VERSION ""

NS_ :

BS_:

BU_:

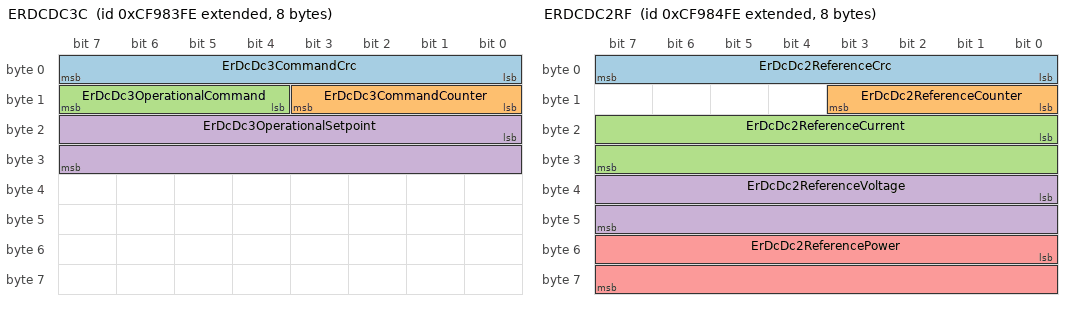
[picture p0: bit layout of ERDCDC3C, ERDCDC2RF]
BO_ 2365162494 ERDCDC3C: 8 Vector__XXX
 SG_ ErDcDc3CommandCrc : 0|8@1+ (1,0) [0|250] "count" Vector__XXX
 SG_ ErDcDc3CommandCounter : 8|4@1+ (1,0) [0|15] "" Vector__XXX
 SG_ ErDcDc3OperationalCommand : 12|4@1+ (1,0) [0|15] "" Vector__XXX
 SG_ ErDcDc3OperationalSetpoint : 16|16@1+ (0.00390625,-125) [-125|125.99609375] "%" Vector__XXX

BO_ 2365162750 ERDCDC2RF: 8 Vector__XXX
 SG_ ErDcDc2ReferenceCrc : 0|8@1+ (1,0) [0|250] "count" Vector__XXX
 SG_ ErDcDc2ReferenceCounter : 8|4@1+ (1,0) [0|15] "" Vector__XXX
 SG_ ErDcDc2ReferenceCurrent : 16|16@1+ (0.125,0) [0|8031.875] "A" Vector__XXX
 SG_ ErDcDc2ReferenceVoltage : 32|16@1+ (0.125,0) [0|8031.875] "V" Vector__XXX
 SG_ ErDcDc2ReferencePower : 48|16@1+ (0.0625,0) [0|4015.9375] "kW" Vector__XXX

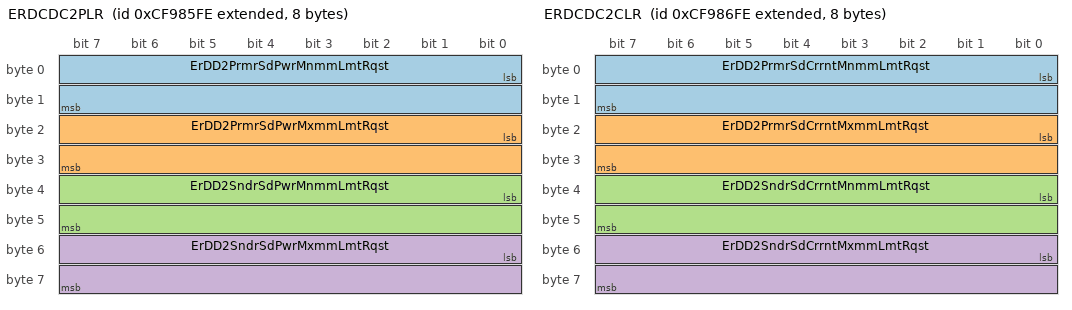
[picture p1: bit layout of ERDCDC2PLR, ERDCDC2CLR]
BO_ 2365163006 ERDCDC2PLR: 8 Vector__XXX
 SG_ ErDD2PrmrSdPwrMnmmLmtRqst : 0|16@1+ (0.00390625,-125) [-125|125.99609375] "%" Vector__XXX
 SG_ ErDD2PrmrSdPwrMxmmLmtRqst : 16|16@1+ (0.00390625,-125) [-125|125.99609375] "%" Vector__XXX
 SG_ ErDD2SndrSdPwrMnmmLmtRqst : 32|16@1+ (0.00390625,-125) [-125|125.99609375] "%" Vector__XXX
 SG_ ErDD2SndrSdPwrMxmmLmtRqst : 48|16@1+ (0.00390625,-125) [-125|125.99609375] "%" Vector__XXX

BO_ 2365163262 ERDCDC2CLR: 8 Vector__XXX
 SG_ ErDD2PrmrSdCrrntMnmmLmtRqst : 0|16@1+ (0.00390625,-125) [-125|125.99609375] "%" Vector__XXX
 SG_ ErDD2PrmrSdCrrntMxmmLmtRqst : 16|16@1+ (0.00390625,-125) [-125|125.99609375] "%" Vector__XXX
 SG_ ErDD2SndrSdCrrntMnmmLmtRqst : 32|16@1+ (0.00390625,-125) [-125|125.99609375] "%" Vector__XXX
 SG_ ErDD2SndrSdCrrntMxmmLmtRqst : 48|16@1+ (0.00390625,-125) [-125|125.99609375] "%" Vector__XXX

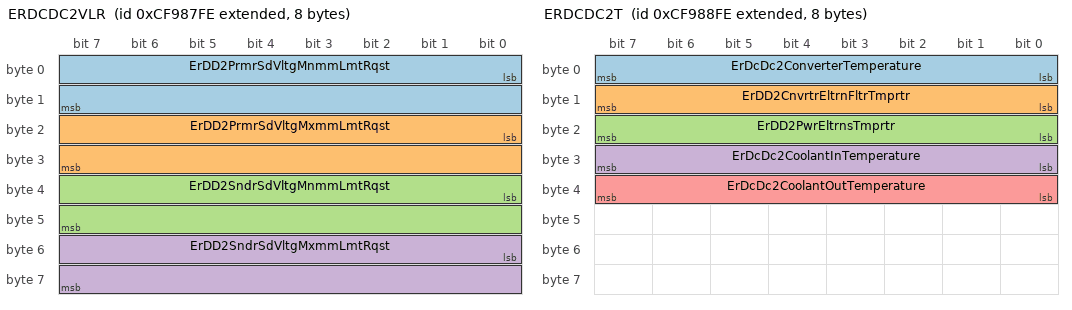
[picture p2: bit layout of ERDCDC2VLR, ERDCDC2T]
BO_ 2365163518 ERDCDC2VLR: 8 Vector__XXX
 SG_ ErDD2PrmrSdVltgMnmmLmtRqst : 0|16@1+ (0.00390625,-125) [0|125.99609375] "%" Vector__XXX
 SG_ ErDD2PrmrSdVltgMxmmLmtRqst : 16|16@1+ (0.00390625,-125) [0|125.99609375] "%" Vector__XXX
 SG_ ErDD2SndrSdVltgMnmmLmtRqst : 32|16@1+ (0.00390625,-125) [0|125.99609375] "%" Vector__XXX
 SG_ ErDD2SndrSdVltgMxmmLmtRqst : 48|16@1+ (0.00390625,-125) [0|125.99609375] "%" Vector__XXX

BO_ 2365163774 ERDCDC2T: 8 Vector__XXX
 SG_ ErDcDc2ConverterTemperature : 0|8@1+ (1,-40) [-40|210] "degC" Vector__XXX
 SG_ ErDD2CnvrtrEltrnFltrTmprtr : 8|8@1+ (1,-40) [-40|210] "degC" Vector__XXX
 SG_ ErDD2PwrEltrnsTmprtr : 16|8@1+ (1,-40) [-40|210] "degC" Vector__XXX
 SG_ ErDcDc2CoolantInTemperature : 24|8@1+ (1,-40) [-40|210] "degC" Vector__XXX
 SG_ ErDcDc2CoolantOutTemperature : 32|8@1+ (1,-40) [-40|210] "degC" Vector__XXX

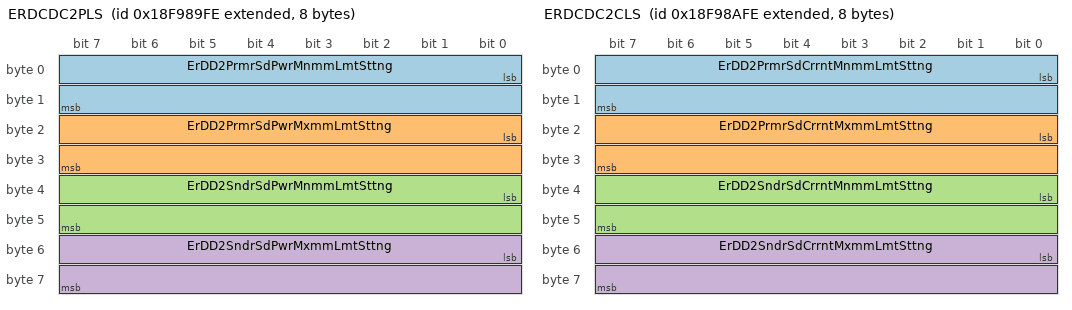
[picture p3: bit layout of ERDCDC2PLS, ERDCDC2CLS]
BO_ 2566490622 ERDCDC2PLS: 8 Vector__XXX
 SG_ ErDD2PrmrSdPwrMnmmLmtSttng : 0|16@1+ (0.00390625,-125) [-125|125.99609375] "%" Vector__XXX
 SG_ ErDD2PrmrSdPwrMxmmLmtSttng : 16|16@1+ (0.00390625,-125) [-125|125.99609375] "%" Vector__XXX
 SG_ ErDD2SndrSdPwrMnmmLmtSttng : 32|16@1+ (0.00390625,-125) [-125|125.99609375] "%" Vector__XXX
 SG_ ErDD2SndrSdPwrMxmmLmtSttng : 48|16@1+ (0.00390625,-125) [-125|125.99609375] "%" Vector__XXX

BO_ 2566490878 ERDCDC2CLS: 8 Vector__XXX
 SG_ ErDD2PrmrSdCrrntMnmmLmtSttng : 0|16@1+ (0.00390625,-125) [-125|125.99609375] "%" Vector__XXX
 SG_ ErDD2PrmrSdCrrntMxmmLmtSttng : 16|16@1+ (0.00390625,-125) [-125|125.99609375] "%" Vector__XXX
 SG_ ErDD2SndrSdCrrntMnmmLmtSttng : 32|16@1+ (0.00390625,-125) [-125|125.99609375] "%" Vector__XXX
 SG_ ErDD2SndrSdCrrntMxmmLmtSttng : 48|16@1+ (0.00390625,-125) [-125|125.99609375] "%" Vector__XXX

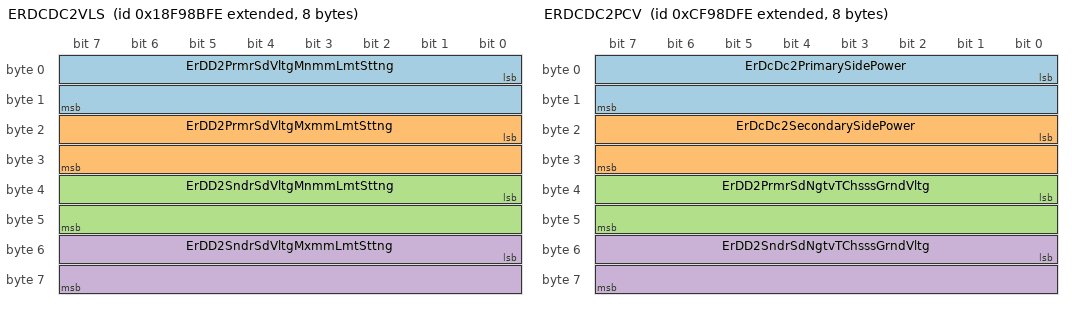
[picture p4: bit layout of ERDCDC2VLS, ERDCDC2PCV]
BO_ 2566491134 ERDCDC2VLS: 8 Vector__XXX
 SG_ ErDD2PrmrSdVltgMnmmLmtSttng : 0|16@1+ (0.00390625,-125) [0|125.99609375] "%" Vector__XXX
 SG_ ErDD2PrmrSdVltgMxmmLmtSttng : 16|16@1+ (0.00390625,-125) [0|125.99609375] "%" Vector__XXX
 SG_ ErDD2SndrSdVltgMnmmLmtSttng : 32|16@1+ (0.00390625,-125) [0|125.99609375] "%" Vector__XXX
 SG_ ErDD2SndrSdVltgMxmmLmtSttng : 48|16@1+ (0.00390625,-125) [0|125.99609375] "%" Vector__XXX

BO_ 2365164798 ERDCDC2LV: 8 Vector__XXX
 SG_ ErDD2CntrllrInptIgntnVltg : 0|16@1+ (0.05,0) [0|3212.75] "V" Vector__XXX
 SG_ ErDD2CntrllrInptUnswthdSlVltg : 16|16@1+ (0.05,0) [0|3212.75] "V" Vector__XXX

BO_ 2365165054 ERDCDC2PCV: 8 Vector__XXX
 SG_ ErDcDc2PrimarySidePower : 0|16@1+ (0.00390625,-125) [-125|125.99609375] "%" Vector__XXX
 SG_ ErDcDc2SecondarySidePower : 16|16@1+ (0.00390625,-125) [-125|125.99609375] "%" Vector__XXX
 SG_ ErDD2PrmrSdNgtvTChsssGrndVltg : 32|16@1+ (0.00390625,-125) [0|125.99609375] "%" Vector__XXX
 SG_ ErDD2SndrSdNgtvTChsssGrndVltg : 48|16@1+ (0.00390625,-125) [0|125.99609375] "%" Vector__XXX

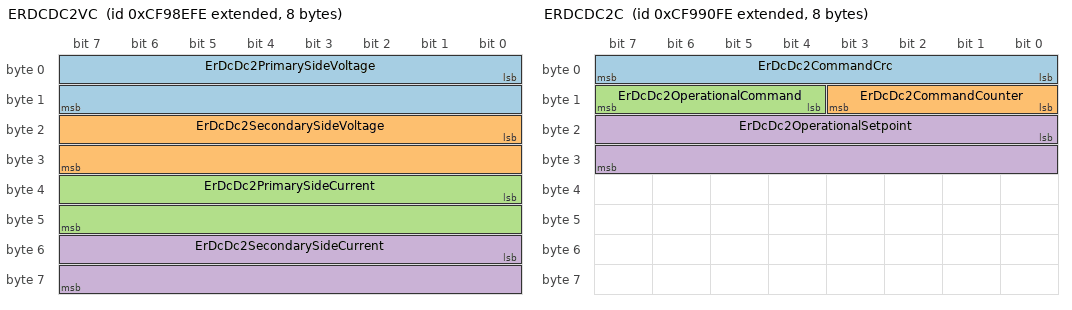
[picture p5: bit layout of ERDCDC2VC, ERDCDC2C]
BO_ 2365165310 ERDCDC2VC: 8 Vector__XXX
 SG_ ErDcDc2PrimarySideVoltage : 0|16@1+ (0.00390625,-125) [0|125.99609375] "%" Vector__XXX
 SG_ ErDcDc2SecondarySideVoltage : 16|16@1+ (0.00390625,-125) [0|125.99609375] "%" Vector__XXX
 SG_ ErDcDc2PrimarySideCurrent : 32|16@1+ (0.00390625,-125) [-125|125.99609375] "%" Vector__XXX
 SG_ ErDcDc2SecondarySideCurrent : 48|16@1+ (0.00390625,-125) [-125|125.99609375] "%" Vector__XXX

BO_ 2365165566 ERDCDC2OS: 8 Vector__XXX
 SG_ ErDcDc2StatusCrc : 0|8@1+ (1,0) [0|250] "count" Vector__XXX
 SG_ ErDcDc2StatusCounter : 8|4@1+ (1,0) [0|15] "" Vector__XXX
 SG_ ErDcDc2OperationalStatus : 12|4@1+ (1,0) [0|15] "" Vector__XXX
 SG_ ErDcDc2HvilStatus : 16|2@1+ (1,0) [0|3] "" Vector__XXX
 SG_ ErDcDc2LoadshedRequest : 18|2@1+ (1,0) [0|3] "" Vector__XXX
 SG_ ErDD2PwrLmtDTPrmrSdCrrntMnmm : 20|2@1+ (1,0) [0|3] "" Vector__XXX
 SG_ ErDD2PwrLmtDTPrmrSdCrrntMxmm : 22|2@1+ (1,0) [0|3] "" Vector__XXX
 SG_ ErDD2PwrLmtDTSndrSdCrrntMnmm : 24|2@1+ (1,0) [0|3] "" Vector__XXX
 SG_ ErDD2PwrLmtDTSndrSdCrrntMxmm : 26|2@1+ (1,0) [0|3] "" Vector__XXX
 SG_ ErDD2PwrLmtDTPrmrSdVltgMnmm : 28|2@1+ (1,0) [0|3] "" Vector__XXX
 SG_ ErDD2PwrLmtDTPrmrSdVltgMxmm : 30|2@1+ (1,0) [0|3] "" Vector__XXX
 SG_ ErDD2PwrLmtDTSndrSdVltgMnmm : 32|2@1+ (1,0) [0|3] "" Vector__XXX
 SG_ ErDD2PwrLmtDTSndrSdVltgMxmm : 34|2@1+ (1,0) [0|3] "" Vector__XXX
 SG_ ErDD2PwrLmtDTCnvrtrTmprtr : 36|2@1+ (1,0) [0|3] "" Vector__XXX
 SG_ ErDD2PwrLmtDTEltrnFltrTmprtr : 38|2@1+ (1,0) [0|3] "" Vector__XXX
 SG_ ErDD2PwrLmtDTPwrEltrnsTmprtr : 40|2@1+ (1,0) [0|3] "" Vector__XXX
 SG_ ErDD2PwrLmtDTUndfndRsn : 42|2@1+ (1,0) [0|3] "" Vector__XXX

BO_ 2365165822 ERDCDC2C: 8 Vector__XXX
 SG_ ErDcDc2CommandCrc : 0|8@1+ (1,0) [0|250] "count" Vector__XXX
 SG_ ErDcDc2CommandCounter : 8|4@1+ (1,0) [0|15] "" Vector__XXX
 SG_ ErDcDc2OperationalCommand : 12|4@1+ (1,0) [0|15] "" Vector__XXX
 SG_ ErDcDc2OperationalSetpoint : 16|16@1+ (0.00390625,-125) [-125|125.99609375] "%" Vector__XXX

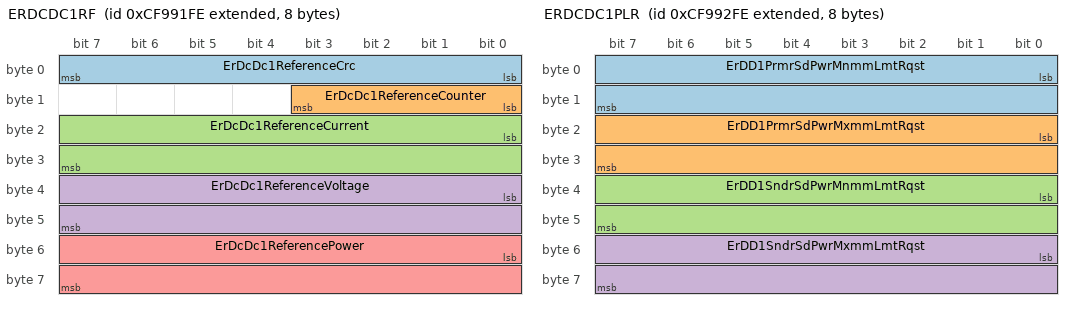
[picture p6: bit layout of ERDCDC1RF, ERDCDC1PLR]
BO_ 2365166078 ERDCDC1RF: 8 Vector__XXX
 SG_ ErDcDc1ReferenceCrc : 0|8@1+ (1,0) [0|250] "count" Vector__XXX
 SG_ ErDcDc1ReferenceCounter : 8|4@1+ (1,0) [0|15] "" Vector__XXX
 SG_ ErDcDc1ReferenceCurrent : 16|16@1+ (0.125,0) [0|8031.875] "A" Vector__XXX
 SG_ ErDcDc1ReferenceVoltage : 32|16@1+ (0.125,0) [0|8031.875] "V" Vector__XXX
 SG_ ErDcDc1ReferencePower : 48|16@1+ (0.0625,0) [0|4015.9375] "kW" Vector__XXX

BO_ 2365166334 ERDCDC1PLR: 8 Vector__XXX
 SG_ ErDD1PrmrSdPwrMnmmLmtRqst : 0|16@1+ (0.00390625,-125) [-125|125.99609375] "%" Vector__XXX
 SG_ ErDD1PrmrSdPwrMxmmLmtRqst : 16|16@1+ (0.00390625,-125) [-125|125.99609375] "%" Vector__XXX
 SG_ ErDD1SndrSdPwrMnmmLmtRqst : 32|16@1+ (0.00390625,-125) [-125|125.99609375] "%" Vector__XXX
 SG_ ErDD1SndrSdPwrMxmmLmtRqst : 48|16@1+ (0.00390625,-125) [-125|125.99609375] "%" Vector__XXX

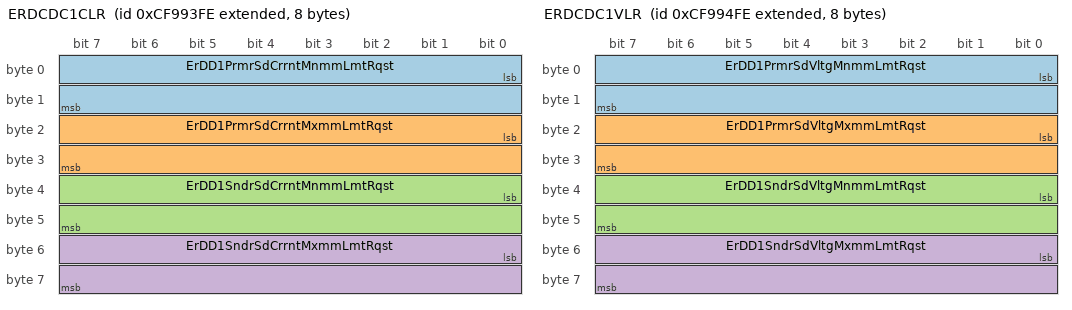
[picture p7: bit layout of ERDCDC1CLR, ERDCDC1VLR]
BO_ 2365166590 ERDCDC1CLR: 8 Vector__XXX
 SG_ ErDD1PrmrSdCrrntMnmmLmtRqst : 0|16@1+ (0.00390625,-125) [-125|125.99609375] "%" Vector__XXX
 SG_ ErDD1PrmrSdCrrntMxmmLmtRqst : 16|16@1+ (0.00390625,-125) [-125|125.99609375] "%" Vector__XXX
 SG_ ErDD1SndrSdCrrntMnmmLmtRqst : 32|16@1+ (0.00390625,-125) [-125|125.99609375] "%" Vector__XXX
 SG_ ErDD1SndrSdCrrntMxmmLmtRqst : 48|16@1+ (0.00390625,-125) [-125|125.99609375] "%" Vector__XXX

BO_ 2365166846 ERDCDC1VLR: 8 Vector__XXX
 SG_ ErDD1PrmrSdVltgMnmmLmtRqst : 0|16@1+ (0.00390625,-125) [0|125.99609375] "%" Vector__XXX
 SG_ ErDD1PrmrSdVltgMxmmLmtRqst : 16|16@1+ (0.00390625,-125) [0|125.99609375] "%" Vector__XXX
 SG_ ErDD1SndrSdVltgMnmmLmtRqst : 32|16@1+ (0.00390625,-125) [0|125.99609375] "%" Vector__XXX
 SG_ ErDD1SndrSdVltgMxmmLmtRqst : 48|16@1+ (0.00390625,-125) [0|125.99609375] "%" Vector__XXX

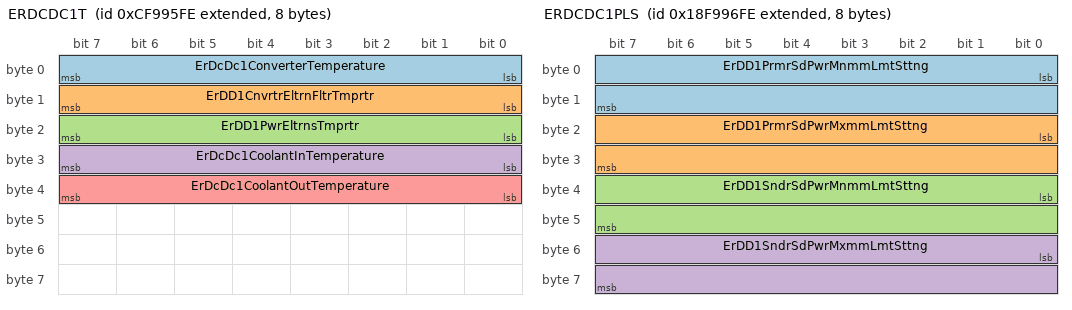
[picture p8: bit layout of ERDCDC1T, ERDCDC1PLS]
BO_ 2365167102 ERDCDC1T: 8 Vector__XXX
 SG_ ErDcDc1ConverterTemperature : 0|8@1+ (1,-40) [-40|210] "degC" Vector__XXX
 SG_ ErDD1CnvrtrEltrnFltrTmprtr : 8|8@1+ (1,-40) [-40|210] "degC" Vector__XXX
 SG_ ErDD1PwrEltrnsTmprtr : 16|8@1+ (1,-40) [-40|210] "degC" Vector__XXX
 SG_ ErDcDc1CoolantInTemperature : 24|8@1+ (1,-40) [-40|210] "degC" Vector__XXX
 SG_ ErDcDc1CoolantOutTemperature : 32|8@1+ (1,-40) [-40|210] "degC" Vector__XXX

BO_ 2566493950 ERDCDC1PLS: 8 Vector__XXX
 SG_ ErDD1PrmrSdPwrMnmmLmtSttng : 0|16@1+ (0.00390625,-125) [-125|125.99609375] "%" Vector__XXX
 SG_ ErDD1PrmrSdPwrMxmmLmtSttng : 16|16@1+ (0.00390625,-125) [-125|125.99609375] "%" Vector__XXX
 SG_ ErDD1SndrSdPwrMnmmLmtSttng : 32|16@1+ (0.00390625,-125) [-125|125.99609375] "%" Vector__XXX
 SG_ ErDD1SndrSdPwrMxmmLmtSttng : 48|16@1+ (0.00390625,-125) [-125|125.99609375] "%" Vector__XXX

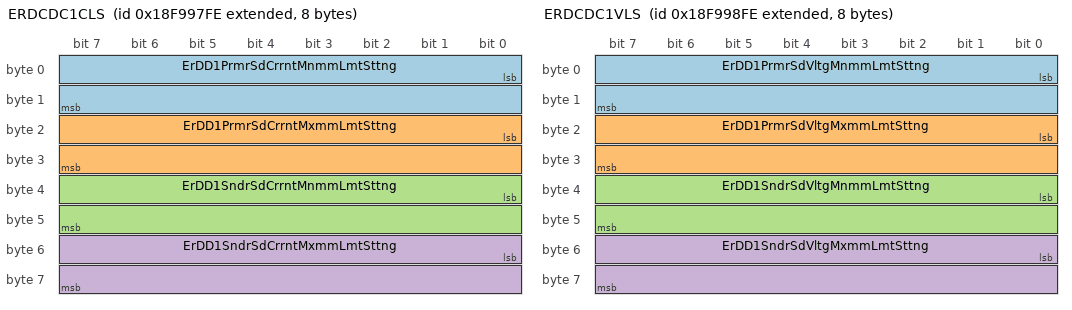
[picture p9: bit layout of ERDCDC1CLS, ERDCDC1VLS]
BO_ 2566494206 ERDCDC1CLS: 8 Vector__XXX
 SG_ ErDD1PrmrSdCrrntMnmmLmtSttng : 0|16@1+ (0.00390625,-125) [-125|125.99609375] "%" Vector__XXX
 SG_ ErDD1PrmrSdCrrntMxmmLmtSttng : 16|16@1+ (0.00390625,-125) [-125|125.99609375] "%" Vector__XXX
 SG_ ErDD1SndrSdCrrntMnmmLmtSttng : 32|16@1+ (0.00390625,-125) [-125|125.99609375] "%" Vector__XXX
 SG_ ErDD1SndrSdCrrntMxmmLmtSttng : 48|16@1+ (0.00390625,-125) [-125|125.99609375] "%" Vector__XXX

BO_ 2566494462 ERDCDC1VLS: 8 Vector__XXX
 SG_ ErDD1PrmrSdVltgMnmmLmtSttng : 0|16@1+ (0.00390625,-125) [0|125.99609375] "%" Vector__XXX
 SG_ ErDD1PrmrSdVltgMxmmLmtSttng : 16|16@1+ (0.00390625,-125) [0|125.99609375] "%" Vector__XXX
 SG_ ErDD1SndrSdVltgMnmmLmtSttng : 32|16@1+ (0.00390625,-125) [0|125.99609375] "%" Vector__XXX
 SG_ ErDD1SndrSdVltgMxmmLmtSttng : 48|16@1+ (0.00390625,-125) [0|125.99609375] "%" Vector__XXX

BO_ 2365168126 ERDCDC1LV: 8 Vector__XXX
 SG_ ErDD1CntrllrInptIgntnVltg : 0|16@1+ (0.05,0) [0|3212.75] "V" Vector__XXX
 SG_ ErDD1CntrllrInptUnswthdSlVltg : 16|16@1+ (0.05,0) [0|3212.75] "V" Vector__XXX

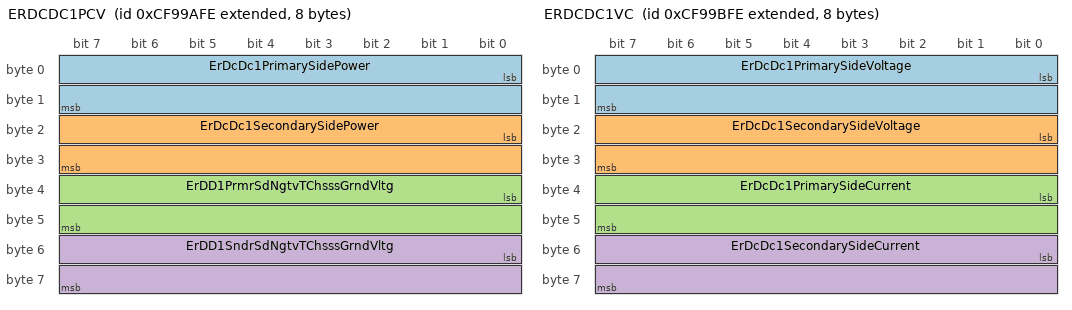
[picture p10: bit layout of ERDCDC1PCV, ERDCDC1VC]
BO_ 2365168382 ERDCDC1PCV: 8 Vector__XXX
 SG_ ErDcDc1PrimarySidePower : 0|16@1+ (0.00390625,-125) [-125|125.99609375] "%" Vector__XXX
 SG_ ErDcDc1SecondarySidePower : 16|16@1+ (0.00390625,-125) [-125|125.99609375] "%" Vector__XXX
 SG_ ErDD1PrmrSdNgtvTChsssGrndVltg : 32|16@1+ (0.00390625,-125) [0|125.99609375] "%" Vector__XXX
 SG_ ErDD1SndrSdNgtvTChsssGrndVltg : 48|16@1+ (0.00390625,-125) [0|125.99609375] "%" Vector__XXX

BO_ 2365168638 ERDCDC1VC: 8 Vector__XXX
 SG_ ErDcDc1PrimarySideVoltage : 0|16@1+ (0.00390625,-125) [0|125.99609375] "%" Vector__XXX
 SG_ ErDcDc1SecondarySideVoltage : 16|16@1+ (0.00390625,-125) [0|125.99609375] "%" Vector__XXX
 SG_ ErDcDc1PrimarySideCurrent : 32|16@1+ (0.00390625,-125) [-125|125.99609375] "%" Vector__XXX
 SG_ ErDcDc1SecondarySideCurrent : 48|16@1+ (0.00390625,-125) [-125|125.99609375] "%" Vector__XXX

BO_ 2365168894 ERDCDC1OS: 8 Vector__XXX
 SG_ ErDcDc1StatusCrc : 0|8@1+ (1,0) [0|250] "count" Vector__XXX
 SG_ ErDcDc1StatusCounter : 8|4@1+ (1,0) [0|15] "" Vector__XXX
 SG_ ErDcDc1OperationalStatus : 12|4@1+ (1,0) [0|15] "" Vector__XXX
 SG_ ErDcDc1HvilStatus : 16|2@1+ (1,0) [0|3] "" Vector__XXX
 SG_ ErDcDc1LoadshedRequest : 18|2@1+ (1,0) [0|3] "" Vector__XXX
 SG_ ErDD1PwrLmtDTPrmrSdCrrntMnmm : 20|2@1+ (1,0) [0|3] "" Vector__XXX
 SG_ ErDD1PwrLmtDTPrmrSdCrrntMxmm : 22|2@1+ (1,0) [0|3] "" Vector__XXX
 SG_ ErDD1PwrLmtDTSndrSdCrrntMnmm : 24|2@1+ (1,0) [0|3] "" Vector__XXX
 SG_ ErDD1PwrLmtDTSndrSdCrrntMxmm : 26|2@1+ (1,0) [0|3] "" Vector__XXX
 SG_ ErDD1PwrLmtDTPrmrSdVltgMnmm : 28|2@1+ (1,0) [0|3] "" Vector__XXX
 SG_ ErDD1PwrLmtDTPrmrSdVltgMxmm : 30|2@1+ (1,0) [0|3] "" Vector__XXX
 SG_ ErDD1PwrLmtDTSndrSdVltgMnmm : 32|2@1+ (1,0) [0|3] "" Vector__XXX
 SG_ ErDD1PwrLmtDTSndrSdVltgMxmm : 34|2@1+ (1,0) [0|3] "" Vector__XXX
 SG_ ErDD1PwrLmtDTCnvrtrTmprtr : 36|2@1+ (1,0) [0|3] "" Vector__XXX
 SG_ ErDD1PwrLmtDTEltrnFltrTmprtr : 38|2@1+ (1,0) [0|3] "" Vector__XXX
 SG_ ErDD1PwrLmtDTPwrEltrnsTmprtr : 40|2@1+ (1,0) [0|3] "" Vector__XXX
 SG_ ErDD1PwrLmtDTUndfndRsn : 42|2@1+ (1,0) [0|3] "" Vector__XXX

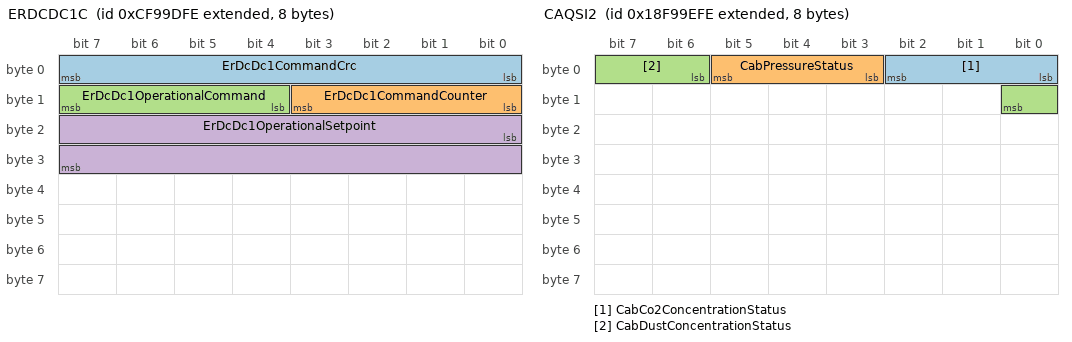
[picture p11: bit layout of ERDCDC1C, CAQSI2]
BO_ 2365169150 ERDCDC1C: 8 Vector__XXX
 SG_ ErDcDc1CommandCrc : 0|8@1+ (1,0) [0|250] "count" Vector__XXX
 SG_ ErDcDc1CommandCounter : 8|4@1+ (1,0) [0|15] "" Vector__XXX
 SG_ ErDcDc1OperationalCommand : 12|4@1+ (1,0) [0|15] "" Vector__XXX
 SG_ ErDcDc1OperationalSetpoint : 16|16@1+ (0.00390625,-125) [-125|125.99609375] "%" Vector__XXX

BO_ 2566495998 CAQSI2: 8 Vector__XXX
 SG_ CabCo2ConcentrationStatus : 0|3@1+ (1,0) [0|7] "" Vector__XXX
 SG_ CabPressureStatus : 3|3@1+ (1,0) [0|7] "" Vector__XXX
 SG_ CabDustConcentrationStatus : 6|3@1+ (1,0) [0|7] "" Vector__XXX

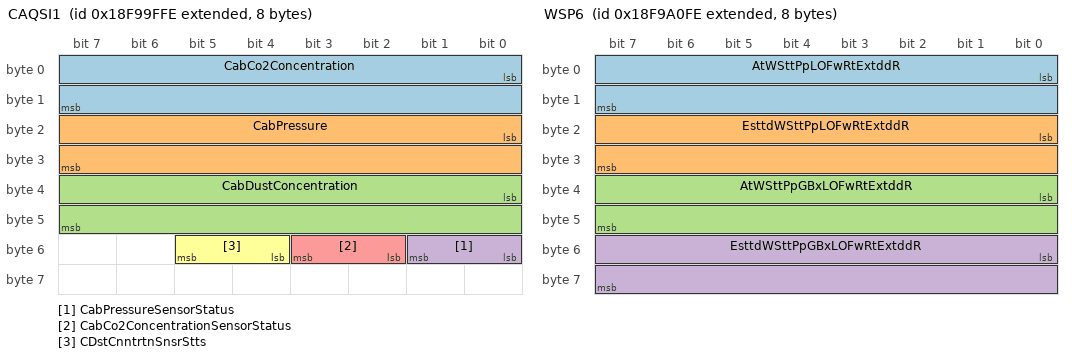
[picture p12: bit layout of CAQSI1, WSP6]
BO_ 2566496254 CAQSI1: 8 Vector__XXX
 SG_ CabCo2Concentration : 0|16@1+ (1,0) [0|64255] "ppm" Vector__XXX
 SG_ CabPressure : 16|16@1+ (0.0078125,-250) [-100|251.9921875] "kPa" Vector__XXX
 SG_ CabDustConcentration : 32|16@1+ (1,-25) [-25|64230] "microg/m3" Vector__XXX
 SG_ CabPressureSensorStatus : 48|2@1+ (1,0) [0|3] "" Vector__XXX
 SG_ CabCo2ConcentrationSensorStatus : 50|2@1+ (1,0) [0|3] "" Vector__XXX
 SG_ CDstCnntrtnSnsrStts : 52|2@1+ (1,0) [0|3] "" Vector__XXX

BO_ 2566496510 WSP6: 8 Vector__XXX
 SG_ AtWSttPpLOFwRtExtddR : 0|16@1+ (0.5,0) [0|32127.5] "l/min" Vector__XXX
 SG_ EsttdWSttPpLOFwRtExtddR : 16|16@1+ (0.5,0) [0|32127.5] "l/min" Vector__XXX
 SG_ AtWSttPpGBxLOFwRtExtddR : 32|16@1+ (0.5,0) [0|32127.5] "l/min" Vector__XXX
 SG_ EsttdWSttPpGBxLOFwRtExtddR : 48|16@1+ (0.5,0) [0|32127.5] "l/min" Vector__XXX

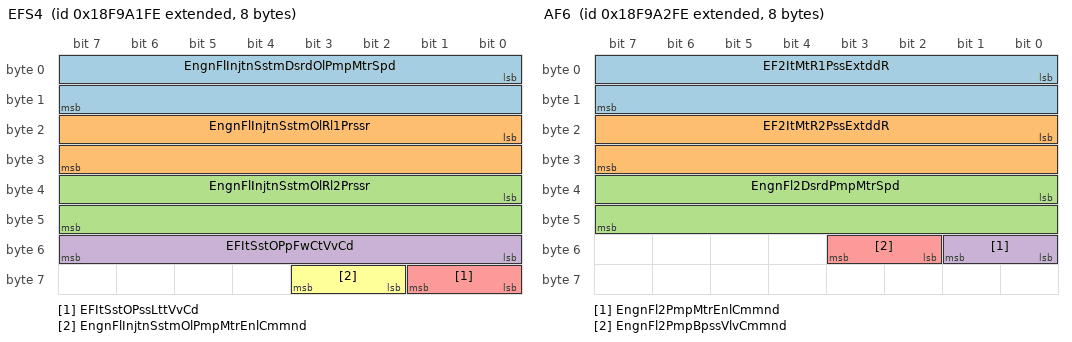
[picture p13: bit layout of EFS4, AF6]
BO_ 2566496766 EFS4: 8 Vector__XXX
 SG_ EngnFlInjtnSstmDsrdOlPmpMtrSpd : 0|16@1+ (0.5,0) [0|32127.5] "rpm" Vector__XXX
 SG_ EngnFlInjtnSstmOlRl1Prssr : 16|16@1+ (0.00390625,0) [0|250.99609375] "MPa" Vector__XXX
 SG_ EngnFlInjtnSstmOlRl2Prssr : 32|16@1+ (0.00390625,0) [0|250.99609375] "MPa" Vector__XXX
 SG_ EFItSstOPpFwCtVvCd : 48|8@1+ (0.4,0) [0|100] "%" Vector__XXX
 SG_ EFItSstOPssLttVvCd : 56|2@1+ (1,0) [0|3] "" Vector__XXX
 SG_ EngnFlInjtnSstmOlPmpMtrEnlCmmnd : 58|2@1+ (1,0) [0|3] "" Vector__XXX

BO_ 2566497022 AF6: 8 Vector__XXX
 SG_ EF2ItMtR1PssExtddR : 0|16@1+ (0.00390625,0) [0|250.99609375] "MPa" Vector__XXX
 SG_ EF2ItMtR2PssExtddR : 16|16@1+ (0.00390625,0) [0|250.99609375] "MPa" Vector__XXX
 SG_ EngnFl2DsrdPmpMtrSpd : 32|16@1+ (0.5,0) [0|32127.5] "rpm" Vector__XXX
 SG_ EngnFl2PmpMtrEnlCmmnd : 48|2@1+ (1,0) [0|3] "" Vector__XXX
 SG_ EngnFl2PmpBpssVlvCmmnd : 50|2@1+ (1,0) [0|3] "" Vector__XXX

BO_ 2566497278 ECDAC: 8 Vector__XXX
 SG_ EngnCtlstDvrtrAttr1Cmmnd : 0|8@1+ (0.4,0) [0|100] "%" Vector__XXX
 SG_ EngnCtlstDvrtrAttr2Cmmnd : 8|8@1+ (0.4,0) [0|100] "%" Vector__XXX

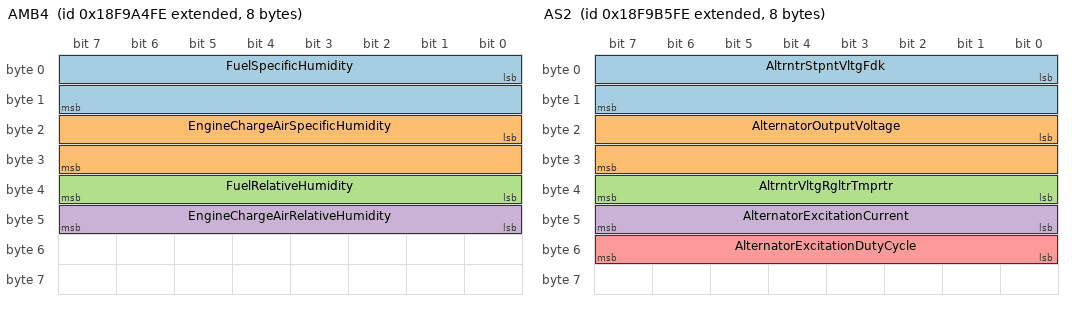
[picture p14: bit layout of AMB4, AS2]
BO_ 2566497534 AMB4: 8 Vector__XXX
 SG_ FuelSpecificHumidity : 0|16@1+ (0.01,0) [0|642.55] "g/kg" Vector__XXX
 SG_ EngineChargeAirSpecificHumidity : 16|16@1+ (0.01,0) [0|642.55] "g/kg" Vector__XXX
 SG_ FuelRelativeHumidity : 32|8@1+ (0.4,0) [0|100] "%" Vector__XXX
 SG_ EngineChargeAirRelativeHumidity : 40|8@1+ (0.4,0) [0|100] "%" Vector__XXX

BO_ 2566497790 EEPCSI2: 8 Vector__XXX
 SG_ Atttt2ExstPttCtSstDstT : 0|32@1+ (1,0) [0|4211081215] "s" Vector__XXX
 SG_ Atttt2ExstPttCtSstDstCt : 32|32@1+ (1,0) [0|4211081215] "count" Vector__XXX

BO_ 2566498046 EEPCSI1: 8 Vector__XXX
 SG_ Atttt1ExstPttCtSstDstT : 0|32@1+ (1,0) [0|4211081215] "s" Vector__XXX
 SG_ Atttt1ExstPttCtSstDstCt : 32|32@1+ (1,0) [0|4211081215] "count" Vector__XXX

BO_ 2566498302 ASI20: 8 Vector__XXX
 SG_ Atttt2TtERtWtNDsExstFdDv : 0|32@1+ (1,0) [0|4211081215] "s" Vector__XXX
 SG_ Atttt2TtEvtCtWtNDsExstFdDv : 32|32@1+ (1,0) [0|4211081215] "count" Vector__XXX

BO_ 2566498558 ASI19: 8 Vector__XXX
 SG_ Aftrtrtmnt2SrIntkHghTmprtrTm : 0|32@1+ (1,0) [0|4211081215] "s" Vector__XXX
 SG_ Aftrtrtmnt2SrIntkHghTmprtrCnt : 32|32@1+ (1,0) [0|4211081215] "count" Vector__XXX

BO_ 2566498814 ASI18: 8 Vector__XXX
 SG_ Aftrtrtmnt2DslExhstFldFrznTm : 0|32@1+ (1,0) [0|4211081215] "s" Vector__XXX
 SG_ Aftrtrtmnt2DslExhstFldFrznCnt : 32|32@1+ (1,0) [0|4211081215] "count" Vector__XXX

BO_ 2566499070 ASI17: 8 Vector__XXX
 SG_ Aftrtrtmnt2SrMlfntnTm : 0|32@1+ (1,0) [0|4211081215] "s" Vector__XXX
 SG_ Aftrtrtmnt2SrMlfntnCnt : 32|32@1+ (1,0) [0|4211081215] "count" Vector__XXX

BO_ 2566499326 ASI16: 8 Vector__XXX
 SG_ Atttt2DsExstFdQtMtT : 0|32@1+ (1,0) [0|4211081215] "s" Vector__XXX
 SG_ Atttt2DsExstFdQtMtCt : 32|32@1+ (1,0) [0|4211081215] "count" Vector__XXX

BO_ 2566499582 ASI15: 8 Vector__XXX
 SG_ Atttt2DsExstFdT1EptT : 0|32@1+ (1,0) [0|4211081215] "s" Vector__XXX
 SG_ Atttt2DsExstFdT1EptCt : 32|32@1+ (1,0) [0|4211081215] "count" Vector__XXX

BO_ 2566499838 ASI14: 8 Vector__XXX
 SG_ AttttTtERtWtNDsExstFdDv : 0|32@1+ (1,0) [0|4211081215] "s" Vector__XXX
 SG_ AttttTtEvtCtWtNDsExstFdDv : 32|32@1+ (1,0) [0|4211081215] "count" Vector__XXX

BO_ 2566500094 ASI13: 8 Vector__XXX
 SG_ AftrtrtmntSrIntkHghTmprtrTm : 0|32@1+ (1,0) [0|4211081215] "s" Vector__XXX
 SG_ AftrtrtmntSrIntkHghTmprtrCnt : 32|32@1+ (1,0) [0|4211081215] "count" Vector__XXX

BO_ 2566500350 ASI12: 8 Vector__XXX
 SG_ Aftrtrtmnt1DslExhstFldFrznTm : 0|32@1+ (1,0) [0|4211081215] "s" Vector__XXX
 SG_ Aftrtrtmnt1DslExhstFldFrznCnt : 32|32@1+ (1,0) [0|4211081215] "count" Vector__XXX

BO_ 2566500606 ASI11: 8 Vector__XXX
 SG_ Aftrtrtmnt1SrMlfntnTm : 0|32@1+ (1,0) [0|4211081215] "s" Vector__XXX
 SG_ Aftrtrtmnt1SrMlfntnCnt : 32|32@1+ (1,0) [0|4211081215] "count" Vector__XXX

BO_ 2566500862 ASI10: 8 Vector__XXX
 SG_ Atttt1DsExstFdQtMtT : 0|32@1+ (1,0) [0|4211081215] "s" Vector__XXX
 SG_ Atttt1DsExstFdQtMtCt : 32|32@1+ (1,0) [0|4211081215] "count" Vector__XXX

BO_ 2566501118 ASI9: 8 Vector__XXX
 SG_ Atttt1DsExstFdT1EptT : 0|32@1+ (1,0) [0|4211081215] "s" Vector__XXX
 SG_ Atttt1DsExstFdT1EptCt : 32|32@1+ (1,0) [0|4211081215] "count" Vector__XXX

BO_ 2499392766 GSF2: 8 Vector__XXX
 SG_ SmltdMnsFrqnOffstExtnddRng : 0|16@1+ (0.01,-321.28) [-321.28|321.27] "Hz" Vector__XXX

BO_ 2566501886 AS2: 8 Vector__XXX
 SG_ AltrntrStpntVltgFdk : 0|16@1+ (0.001,0) [0|64.255] "V" Vector__XXX
 SG_ AlternatorOutputVoltage : 16|16@1+ (0.001,0) [0|64.255] "V" Vector__XXX
 SG_ AltrntrVltgRgltrTmprtr : 32|8@1+ (1,-40) [-40|210] "degC" Vector__XXX
 SG_ AlternatorExcitationCurrent : 40|8@1+ (0.25,0) [0|62.5] "A" Vector__XXX
 SG_ AlternatorExcitationDutyCycle : 48|8@1+ (0.4,0) [0|100] "%" Vector__XXX

BO_ 2499417598 GSF: 8 Vector__XXX
 SG_ RtvPwrRmtInptCmpnstnFtr : 32|16@1+ (0.01,-321.27) [-321.27|321.28] "%" Vector__XXX
 SG_ RlPwrRmtInptCmpnstnFtr : 48|16@1+ (0.01,-321.27) [-321.27|321.28] "%" Vector__XXX

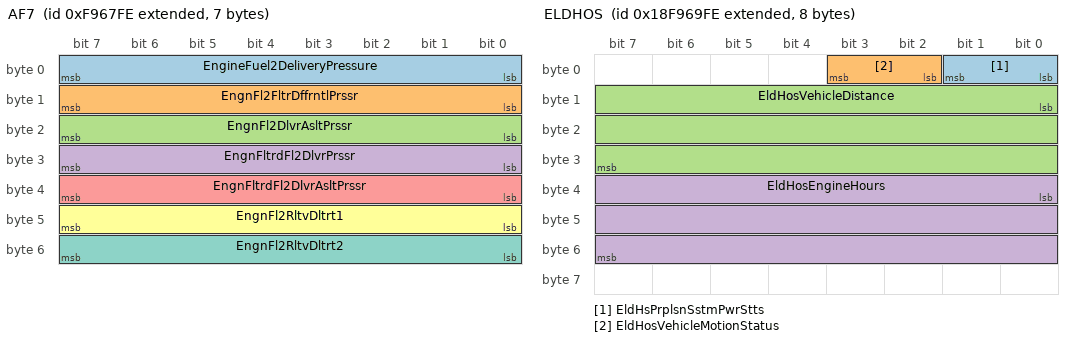
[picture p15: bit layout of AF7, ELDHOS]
BO_ 2163828734 AF7: 7 Vector__XXX
 SG_ EngineFuel2DeliveryPressure : 0|8@1+ (4,0) [0|1000] "kPa" Vector__XXX
 SG_ EngnFl2FltrDffrntlPrssr : 8|8@1+ (2,0) [0|500] "kPa" Vector__XXX
 SG_ EngnFl2DlvrAsltPrssr : 16|8@1+ (4,0) [0|1000] "kPa" Vector__XXX
 SG_ EngnFltrdFl2DlvrPrssr : 24|8@1+ (4,0) [0|1000] "kPa" Vector__XXX
 SG_ EngnFltrdFl2DlvrAsltPrssr : 32|8@1+ (4,0) [0|1000] "kPa" Vector__XXX
 SG_ EngnFl2RltvDltrt1 : 40|8@1+ (0.25,0) [0|62.5] "" Vector__XXX
 SG_ EngnFl2RltvDltrt2 : 48|8@1+ (0.25,0) [0|62.5] "" Vector__XXX

BO_ 2566482174 ECDAI: 8 Vector__XXX
 SG_ EngnCtlstDvrtrAttr1Pstn : 0|8@1+ (0.4,0) [0|100] "%" Vector__XXX
 SG_ EngnCtlstDvrtrAttr2Pstn : 8|8@1+ (0.4,0) [0|100] "%" Vector__XXX

BO_ 2566482430 ELDHOS: 8 Vector__XXX
 SG_ EldHsPrplsnSstmPwrStts : 0|2@1+ (1,0) [0|3] "" Vector__XXX
 SG_ EldHosVehicleMotionStatus : 2|2@1+ (1,0) [0|3] "" Vector__XXX
 SG_ EldHosVehicleDistance : 8|24@1+ (1.6,0) [0|26319256] "km" Vector__XXX
 SG_ EldHosEngineHours : 32|24@1+ (0.1,0) [0|1644953.5] "h" Vector__XXX

CM_ BO_ 2365162494 "ER DC/DC Converter 3 Control";
CM_ SG_ 2365162494 ErDcDc3CommandCrc "ER DC/DC 3 Command CRC: The CRC is defined as follows: - Length: 8 bits- Polynomial: x^8+x^5+x^3+x^2+x+1- Initial Value: FFh- Input Data Reflection: Not reflected- Result Data Reflection: Not reflected- XOR value: FFh SAE makes no claim of the functi...";
CM_ SG_ 2365162494 ErDcDc3CommandCounter "ER DC/DC 3 Command  Counter: The message counter is used to detect situations where the transmitting ECU malfunction repeats the same frame all the time. The receiver of the information may use the counter parameter to detect this situation. The tran...";
CM_ SG_ 2365162494 ErDcDc3OperationalCommand "ER DC/DC 3 Operational Command: Command to enable or disable operation.0000b = Disable - in this mode all high voltage switching is disabled0001b = Standby - system is ready and waiting for command to enter control modes0010b = Power Down - stop all ...";
CM_ SG_ 2365162494 ErDcDc3OperationalSetpoint "ER DC/DC 3 Operational Setpoint: The set point for regulating the DC/DC Converter per SPN 24151 (ER DC/DC 3 Operational Command).  When in Voltage control modes (states 0100b and 0101b of SPN 24151 (ER DC/DC 3 Operational Command)), the operational r...";
CM_ BO_ 2365162750 "ER DC/DC Converter 2 References";
CM_ SG_ 2365162750 ErDcDc2ReferenceCrc "ER DC/DC 2 Reference CRC: The CRC is defined as follows: - Length: 8 bits- Polynomial: x^8+x^5+x^3+x^2+x+1- Initial Value: FFh- Input Data Reflection: Not reflected- Result Data Reflection: Not reflected- XOR value: FFh SAE makes no claim of the func...";
CM_ SG_ 2365162750 ErDcDc2ReferenceCounter "ER DC/DC 2 Reference Counter: The message counter is used to detect situations where the transmitting ECU malfunction repeats the same frame all the time. The receiver of the information may use the counter parameter to detect this situation. The tra...";
CM_ SG_ 2365162750 ErDcDc2ReferenceCurrent "ER DC/DC 2 Reference Current: This value is used for converting inverter current in percent to units of Amps (RMS or DC).(Value in Amps) = (Percent Value)/(100%) * (Reference Current)For example, if this parameter has a value of 200 A and the percent...";
CM_ SG_ 2365162750 ErDcDc2ReferenceVoltage "ER DC/DC 2 Reference Voltage: This value is used for converting inverter voltage in percent to units of Volts (RMS or DC).(Value in Volts) = (Percent Value)/(100%) * (Reference Voltage)For example, if this parameter has a value of 400 V and the perce...";
CM_ SG_ 2365162750 ErDcDc2ReferencePower "ER DC/DC 2 Reference Power: This value is used for converting power in percent to units of kW.  (Value in kW) = (Percent Value)/(100%) * (Reference Power)For example, if this parameter has a value of 400 kW and the percent value is equal to 75%, then...";
CM_ BO_ 2365163006 "ER DC/DC Converter 2 Power Limits Request";
CM_ SG_ 2365163006 ErDD2PrmrSdPwrMnmmLmtRqst "ER DC/DC 2 Primary Side Power Minimum Limit Request: The minimum allowed primary side power requested by a separate device.   Under normal conditions this requested limit would be reflected in SPN 24123 (ER DC/DC 2 Primary Side Power Minimum Limit Se...";
CM_ SG_ 2365163006 ErDD2PrmrSdPwrMxmmLmtRqst "ER DC/DC 2 Primary Side Power Maximum Limit Request: The maximum allowed primary side power requested by a separate device.   Under normal conditions this requested limit would be reflected in SPN 24124 (ER DC/DC 2 Primary Side Power Maximum Limit Se...";
CM_ SG_ 2365163006 ErDD2SndrSdPwrMnmmLmtRqst "ER DC/DC 2 Secondary Side Power Minimum Limit Request: The minimum allowed secondary side power requested by a separate device.   Under normal conditions this requested limit would be reflected in SPN 24125 (ER DC/DC 2 Secondary Side Power Minimum Li...";
CM_ SG_ 2365163006 ErDD2SndrSdPwrMxmmLmtRqst "ER DC/DC 2 Secondary Side Power Maximum Limit Request: The maximum allowed secondary side power requested by a separate device.   Under normal conditions this requested limit would be reflected in SPN 24126 (ER DC/DC 2 Secondary Side Power Maximum Li...";
CM_ BO_ 2365163262 "ER DC/DC Converter 2 Current Limits Request";
CM_ SG_ 2365163262 ErDD2PrmrSdCrrntMnmmLmtRqst "ER DC/DC 2 Primary Side Current Minimum Limit Request: The minimum (negative) allowed Primary Side current requested by a separate device.  Under normal conditions this requested limit would be reflected in SPN 24119 (ER DC/DC 2 Primary Side Current ...";
CM_ SG_ 2365163262 ErDD2PrmrSdCrrntMxmmLmtRqst "ER DC/DC 2 Primary Side Current Maximum Limit Request: The maximum allowed Primary Side current requested by a separate device.  Under normal conditions this requested limit would be reflected in SPN 24120 (ER DC/DC 2 Primary Side Current Maximum Lim...";
CM_ SG_ 2365163262 ErDD2SndrSdCrrntMnmmLmtRqst "ER DC/DC 2 Secondary Side Current Minimum Limit Request: The minimum (negative) allowed Secondary Side current requested by a separate device.   Under normal conditions this requested limit would be reflected in SPN 24121 (ER DC/DC 2 Secondary Side C...";
CM_ SG_ 2365163262 ErDD2SndrSdCrrntMxmmLmtRqst "ER DC/DC 2 Secondary Side Current Maximum Limit Request: The maximum allowed Secondary Side current requested by a separate device.   Under normal conditions this requested limit would be reflected in SPN 24122 (ER DC/DC 2 Secondary Side Current Maxi...";
CM_ BO_ 2365163518 "ER DC/DC Converter 2 Voltage Limits Request";
CM_ SG_ 2365163518 ErDD2PrmrSdVltgMnmmLmtRqst "ER DC/DC 2 Primary Side Voltage Minimum Limit Request: The minimum allowed Primary Side voltage requested by a separate device.   Under normal conditions this requested limit would be reflected in SPN 24115 (ER DC/DC 2 Primary Side Voltage Minimum Li...";
CM_ SG_ 2365163518 ErDD2PrmrSdVltgMxmmLmtRqst "ER DC/DC 2 Primary Side Voltage Maximum Limit Request: The maximum allowed Primary Side voltage requested by a separate device.   Under normal conditions this requested limit would be reflected in SPN 24116 (ER DC/DC 2 Primary Side Voltage Maximum Li...";
CM_ SG_ 2365163518 ErDD2SndrSdVltgMnmmLmtRqst "ER DC/DC 2 Secondary Side Voltage Minimum Limit Request: The minimum allowed Secondary Side voltage requested by a separate device.   Under normal conditions this requested limit would be reflected in SPN 24117 (ER DC/DC 2 Secondary Side Voltage Mini...";
CM_ SG_ 2365163518 ErDD2SndrSdVltgMxmmLmtRqst "ER DC/DC 2 Secondary Side Voltage Maximum Limit Request: The maximum allowed Secondary Side voltage requested by a separate device.   Under normal conditions this requested limit would be reflected in SPN 24118 (ER DC/DC 2 Secondary Side Voltage Maxi...";
CM_ BO_ 2365163774 "ER DC/DC Converter 2 Temperatures";
CM_ SG_ 2365163774 ErDcDc2ConverterTemperature "ER DC/DC 2 Converter Temperature: Parameter indicating the temperature of the Extended Range DC/DC Converter (e.g, controller, circuit board, enclosure).";
CM_ SG_ 2365163774 ErDD2CnvrtrEltrnFltrTmprtr "ER DC/DC 2 Converter Electronic Filter Temperature: Parameter indicating the temperature of the electronic components that make up the Extended Range DC/DC Converter filter.";
CM_ SG_ 2365163774 ErDD2PwrEltrnsTmprtr "ER DC/DC 2 Power Electronics Temperature: Parameter indicating the temperature of the Extended Range DC/DC Converter power electronics components (e.g, switch or heatsink).";
CM_ SG_ 2365163774 ErDcDc2CoolantInTemperature "ER DC/DC 2 Coolant  In Temperature: Parameter indicating the temperature of the Extended Range DC/DC Converter Coolant measured at the input of the converter";
CM_ SG_ 2365163774 ErDcDc2CoolantOutTemperature "ER DC/DC 2 Coolant Out Temperature: Parameter indicating the temperature of the Extended Range DC/DC Converter Coolant measured at the output of the converter";
CM_ BO_ 2566490622 "ER DC/DC Converter 2 Power Limit Settings";
CM_ SG_ 2566490622 ErDD2PrmrSdPwrMnmmLmtSttng "ER DC/DC 2 Primary Side Power Minimum Limit Setting: Reports the active minimum primary side power limit of the Extended Range DC/DC Converter.  The setting may be requested by a separate device (via SPN 24140 (ER DC/DC 2 Primary Side Power Minimum L...";
CM_ SG_ 2566490622 ErDD2PrmrSdPwrMxmmLmtSttng "ER DC/DC 2 Primary Side Power Maximum Limit Setting: Reports the active maximum primary side power limit of the Extended Range DC/DC Converter.  The setting may be requested by a separate device (via SPN 24141 (ER DC/DC 2 Primary Side Power Maximum L...";
CM_ SG_ 2566490622 ErDD2SndrSdPwrMnmmLmtSttng "ER DC/DC 2 Secondary Side Power Minimum Limit Setting: Reports the active minimum secondary side power limit of the Extended Range DC/DC Converter.  The setting may be requested by a separate device (via SPN 24142 (ER DC/DC 2 Secondary Side Power Min...";
CM_ SG_ 2566490622 ErDD2SndrSdPwrMxmmLmtSttng "ER DC/DC 2 Secondary Side Power Maximum Limit Setting: Reports the active maximum secondary side power limit of the Extended Range DC/DC Converter.  The setting may be requested by a separate device (via SPN 24143 (ER DC/DC 2 Secondary Side Power Max...";
CM_ BO_ 2566490878 "ER DC/DC Converter 2 Current Limits Settings";
CM_ SG_ 2566490878 ErDD2PrmrSdCrrntMnmmLmtSttng "ER DC/DC 2 Primary Side Current Minimum Limit Setting: Reports the active minimum limit (negative) on the Primary Side current of the Extended Range DC/DC Converter.  The setting may be requested by a separate device (via SPN 24136 (ER DC/DC 2 Primar...";
CM_ SG_ 2566490878 ErDD2PrmrSdCrrntMxmmLmtSttng "ER DC/DC 2 Primary Side Current Maximum Limit Setting: Reports the active maximum limit on the Primary Side current of the Extended Range DC/DC Converter.  The setting may be requested by a separate device (via SPN 24137 (ER DC/DC 2 Primary Side Curr...";
CM_ SG_ 2566490878 ErDD2SndrSdCrrntMnmmLmtSttng "ER DC/DC 2 Secondary Side Current Minimum Limit Setting: Reports the active minimum limit (negative) on the Secondary Side current of the Extended Range DC/DC Converter.  The setting may be requested by a separate device (via SPN 24138 (ER DC/DC 2 Se...";
CM_ SG_ 2566490878 ErDD2SndrSdCrrntMxmmLmtSttng "ER DC/DC 2 Secondary Side Current Maximum Limit Setting: Reports the active maximum limit on the Secondary Side current of the Extended Range DC/DC Converter.  The setting may be requested by a separate device (via SPN 24139 (ER DC/DC 2 Secondary Sid...";
CM_ BO_ 2566491134 "ER DC/DC Converter 2 Voltage Limit Settings";
CM_ SG_ 2566491134 ErDD2PrmrSdVltgMnmmLmtSttng "ER DC/DC 2 Primary Side Voltage Minimum Limit Setting: Reports the active minimum limit on the Primary Side voltage of the Extended Range DC/DC Converter.  The setting may be requested by a separate device (via SPN 24132 (ER DC/DC 2 Primary Side Volt...";
CM_ SG_ 2566491134 ErDD2PrmrSdVltgMxmmLmtSttng "ER DC/DC 2 Primary Side Voltage Maximum Limit Setting: Reports the active maximum limit on the Primary Side voltage of the Extended Range DC/DC Converter.  The setting may be requested by a separate device (via SPN 24133 (ER DC/DC 2 Primary Side Volt...";
CM_ SG_ 2566491134 ErDD2SndrSdVltgMnmmLmtSttng "ER DC/DC 2 Secondary Side Voltage Minimum Limit Setting: Reports the active minimum limit on the Secondary Side voltage of the Extended Range DC/DC Converter.  The setting may be requested by a separate device (via SPN 24134 (ER DC/DC 2 Secondary Sid...";
CM_ SG_ 2566491134 ErDD2SndrSdVltgMxmmLmtSttng "ER DC/DC 2 Secondary Side Voltage Maximum Limit Setting: Reports the active maximum limit on the Secondary Side voltage of the Extended Range DC/DC Converter.  The setting may be requested by a separate device (via SPN 24135 (ER DC/DC 2 Secondary Sid...";
CM_ BO_ 2365164798 "ER DC/DC Converter 2 Low Voltage";
CM_ SG_ 2365164798 ErDD2CntrllrInptIgntnVltg "ER DC/DC 2 Controller Input Ignition Voltage: Ignition voltage (i.e. switched) supplied to the  Extended Range DC/DC Converter controller.";
CM_ SG_ 2365164798 ErDD2CntrllrInptUnswthdSlVltg "ER DC/DC 2 Controller Input Unswitched SLI Voltage: Continuously supplied SLI power to this instance of the Extended Range DC/DC Converter controller.";
CM_ BO_ 2365165054 "ER DC/DC Converter 2 Power and Chassis Voltage";
CM_ SG_ 2365165054 ErDcDc2PrimarySidePower "ER DC/DC 2 Primary Side Power: Indicates the Primary Side power measured at the Extended Range DC/DC Converter.  The Primary Side power is positive if the converter is flowing current from the Secondary Side to the Primary side.  The Primary Side pow...";
CM_ SG_ 2365165054 ErDcDc2SecondarySidePower "ER DC/DC 2 Secondary Side Power: Indicates the Secondary Side power measured at the Extended Range DC/DC Converter.  The Secondary Side power is positive if the converter is flowing current from the Primary Side to the Secondary side.  The Secondary ...";
CM_ SG_ 2365165054 ErDD2PrmrSdNgtvTChsssGrndVltg "ER DC/DC 2 Primary Side Negative to Chassis Ground Voltage: The voltage level as measured by the ER DC/DC between the Primary Side negative ER DC bus and the chassis of the ER DC/DC enclosure.  This voltage can be used for system level monitoring of ...";
CM_ SG_ 2365165054 ErDD2SndrSdNgtvTChsssGrndVltg "ER DC/DC 2 Secondary Side Negative to Chassis Ground Voltage: The voltage level as measured by the ER DC/DC between the Secondary Side negative ER DC bus and the chassis of the ER DC/DC enclosure.  This voltage can be used for system level monitoring...";
CM_ BO_ 2365165310 "ER DC/DC Converter 2 Voltage and Current";
CM_ SG_ 2365165310 ErDcDc2PrimarySideVoltage "ER DC/DC 2 Primary Side Voltage: Indicates the measured Primary Side voltage measured at the point of control inside the Extended Range DC/DC Converter.Refer to SPN 24147 (ER DC/DC 2 Reference Voltage) to convert % to Volts.";
CM_ SG_ 2365165310 ErDcDc2SecondarySideVoltage "ER DC/DC 2 Secondary Side Voltage: Indicates the measured Secondary Side voltage measured at the point of control inside the Extended Range DC/DC Converter.Refer to SPN 24147 (ER DC/DC 2 Reference Voltage) to convert % to Volts.";
CM_ SG_ 2365165310 ErDcDc2PrimarySideCurrent "ER DC/DC 2 Primary Side Current: Indicates the measured Primary Side current measured at the point of control inside the Extended Range DC/DC Converter.  The current is positive if the converter is flowing current from the Secondary to the Primary Si...";
CM_ SG_ 2365165310 ErDcDc2SecondarySideCurrent "ER DC/DC 2 Secondary Side Current: Indicates the measured Secondary Side current measured at the point of control inside the Extended Range DC/DC Converter.  The current is positive if the converter is flowing current from the Primary to the Secondar...";
CM_ BO_ 2365165566 "ER DC/DC Converter 2 Operating Status";
CM_ SG_ 2365165566 ErDcDc2StatusCrc "ER DC/DC 2 Status CRC: The CRC is defined as follows: - Length: 8 bits- Polynomial: x^8+x^5+x^3+x^2+x+1- Initial Value: FFh- Input Data Reflection: Not reflected- Result Data Reflection: Not reflected- XOR value: FFh SAE makes no claim of the functio...";
CM_ SG_ 2365165566 ErDcDc2StatusCounter "ER DC/DC 2 Status Counter: The message counter is used to detect situations where the transmitting ECU malfunction repeats the same frame all the time. The receiver of the information may use the counter parameter to detect this situation. The transm...";
CM_ SG_ 2365165566 ErDcDc2OperationalStatus "ER DC/DC 2 Operational Status: Operating state of the Extended Range DC/DC Converter0000b = Disabled - In this mode all high voltage switching is disabled0001b = Initialization - The device is powering up.  This process may include both internal chec...";
CM_ SG_ 2365165566 ErDcDc2HvilStatus "ER DC/DC 2 HVIL Status: High Voltage Interlock Loop (HVIL) state of the Extended Range DC/DC Converter.00b = HVIL Closed01b = HVIL Open10b = Error11b = Not Available";
CM_ SG_ 2365165566 ErDcDc2LoadshedRequest "ER DC/DC 2 Loadshed Request: The loadshed request is a request to the controlling device to reduce the Extended Range DC/DC Converter loads.  The Loadshed Requested state is an indication that this Extended Range DC/DC Converter has a malfunction or ...";
CM_ SG_ 2365165566 ErDD2PwrLmtDTPrmrSdCrrntMnmm "ER DC/DC 2 Power Limit due to Primary Side Current Minimum: Indicates whether or not output power is being limited due to Primary Side current (see SPN 24107 (ER DC/DC 2 Primary Side Current)) approaching or exceeding the minimum limit (see SPN 24119...";
CM_ SG_ 2365165566 ErDD2PwrLmtDTPrmrSdCrrntMxmm "ER DC/DC 2 Power Limit due to Primary Side Current Maximum: Indicates whether or not output power is being limited due to Primary Side current (see SPN 24107 (ER DC/DC 2 Primary Side Current)) approaching or exceeding the maximum limit (see SPN 24120...";
CM_ SG_ 2365165566 ErDD2PwrLmtDTSndrSdCrrntMnmm "ER DC/DC 2 Power Limit due to Secondary Side Current Minimum: Indicates whether or not output power is being limited due to Secondary Side current (see SPN 24108 (ER DC/DC 2 Secondary Side Current)) approaching or exceeding the minimum limit (see SPN...";
CM_ SG_ 2365165566 ErDD2PwrLmtDTSndrSdCrrntMxmm "ER DC/DC 2 Power Limit due to Secondary Side Current Maximum: Indicates whether or not output power is being limited due to Secondary Side current (see SPN 24108 (ER DC/DC 2 Secondary Side Current)) approaching or exceeding the maximum limit (see SPN...";
CM_ SG_ 2365165566 ErDD2PwrLmtDTPrmrSdVltgMnmm "ER DC/DC 2 Power Limit due to Primary Side Voltage Minimum: Indicates whether or not output power is being limited due to Primary Side voltage (see SPN 24105 (ER DC/DC 2 Primary Side Voltage)) approaching or exceeding the minimum limit (see SPN 24115...";
CM_ SG_ 2365165566 ErDD2PwrLmtDTPrmrSdVltgMxmm "ER DC/DC 2 Power Limit due to Primary Side Voltage Maximum: Indicates whether or not output power is being limited due to Primary Side voltage (see SPN 24105 (ER DC/DC 2 Primary Side Voltage)) approaching or exceeding the maximum limit (see SPN 24116...";
CM_ SG_ 2365165566 ErDD2PwrLmtDTSndrSdVltgMnmm "ER DC/DC 2 Power Limit due to Secondary Side Voltage Minimum: Indicates whether or not output power is being limited due to Secondary Side voltage (see SPN 24106 (ER DC/DC 2 Secondary Side Voltage)) approaching or exceeding the minimum limit (see SPN...";
CM_ SG_ 2365165566 ErDD2PwrLmtDTSndrSdVltgMxmm "ER DC/DC 2 Power Limit due to Secondary Side Voltage Maximum: Indicates whether or not output power is being limited due to Secondary Side voltage (see SPN 24106 (ER DC/DC 2 Secondary Side Voltage)) approaching or exceeding the maximum limit (see SPN...";
CM_ SG_ 2365165566 ErDD2PwrLmtDTCnvrtrTmprtr "ER DC/DC 2 Power Limit due to Converter Temperature: Indicates whether or not output power is being limited due to Converter Temperature (see SPN 24127 (ER DC/DC 2 Converter Temperature)) approaching or exceeding the maximum limit.00b = No power limi...";
CM_ SG_ 2365165566 ErDD2PwrLmtDTEltrnFltrTmprtr "ER DC/DC 2 Power Limit due to Electronic Filter Temperature: Indicates whether or not output power is being limited due to Output Electronic Filter Temperature (see SPN 24128 (ER DC/DC 2 Converter Electronic Filter Temperature)) approaching or exceed...";
CM_ SG_ 2365165566 ErDD2PwrLmtDTPwrEltrnsTmprtr "ER DC/DC 2 Power Limit due to Power Electronics Temperature: Indicates whether or not output power is being limited due to Power Electronics Temperature (see SPN 24129 (ER DC/DC 2 Power Electronics Temperature)) approaching or exceeding the maximum l...";
CM_ SG_ 2365165566 ErDD2PwrLmtDTUndfndRsn "ER DC/DC 2 Power Limit due to Undefined Reason: Indicates whether or not output power is being limited due to an undefined reason.00b = No power limit for this reason01b = Power limited for this reason10b = Error11b = Not Available";
CM_ BO_ 2365165822 "ER DC/DC Converter 2 Control";
CM_ SG_ 2365165822 ErDcDc2CommandCrc "ER DC/DC 2 Command CRC: The CRC is defined as follows: - Length: 8 bits- Polynomial: x^8+x^5+x^3+x^2+x+1- Initial Value: FFh- Input Data Reflection: Not reflected- Result Data Reflection: Not reflected- XOR value: FFh SAE makes no claim of the functi...";
CM_ SG_ 2365165822 ErDcDc2CommandCounter "ER DC/DC 2 Command  Counter: The message counter is used to detect situations where the transmitting ECU malfunction repeats the same frame all the time. The receiver of the information may use the counter parameter to detect this situation. The tran...";
CM_ SG_ 2365165822 ErDcDc2OperationalCommand "ER DC/DC 2 Operational Command: Command to enable or disable operation.0000b = Disable - in this mode all high voltage switching is disabled0001b = Standby - system is ready and waiting for command to enter control modes0010b = Power Down - stop all ...";
CM_ SG_ 2365165822 ErDcDc2OperationalSetpoint "ER DC/DC 2 Operational Setpoint: The set point for regulating the DC/DC Converter per SPN 24086 (ER DC/DC 2 Operational Command).  When in Voltage control modes (states 0100b and 0101b of SPN 24086 (ER DC/DC 2 Operational Command)), the operational r...";
CM_ BO_ 2365166078 "ER DC/DC Converter 1 References";
CM_ SG_ 2365166078 ErDcDc1ReferenceCrc "ER DC/DC 1 Reference CRC: The CRC is defined as follows: - Length: 8 bits- Polynomial: x^8+x^5+x^3+x^2+x+1- Initial Value: FFh- Input Data Reflection: Not reflected- Result Data Reflection: Not reflected- XOR value: FFh SAE makes no claim of the func...";
CM_ SG_ 2365166078 ErDcDc1ReferenceCounter "ER DC/DC 1 Reference Counter: The message counter is used to detect situations where the transmitting ECU malfunction repeats the same frame all the time. The receiver of the information may use the counter parameter to detect this situation. The tra...";
CM_ SG_ 2365166078 ErDcDc1ReferenceCurrent "ER DC/DC 1 Reference Current: This value is used for converting inverter current in percent to units of Amps (RMS or DC).(Value in Amps) = (Percent Value)/(100%) * (Reference Current)For example, if this parameter has a value of 200 A and the percent...";
CM_ SG_ 2365166078 ErDcDc1ReferenceVoltage "ER DC/DC 1 Reference Voltage: This value is used for converting inverter voltage in percent to units of Volts (RMS or DC).(Value in Volts) = (Percent Value)/(100%) * (Reference Voltage)For example, if this parameter has a value of 400 V and the perce...";
CM_ SG_ 2365166078 ErDcDc1ReferencePower "ER DC/DC 1 Reference Power: This value is used for converting power in percent to units of kW.  (Value in kW) = (Percent Value)/(100%) * (Reference Power)For example, if this parameter has a value of 400 kW and the percent value is equal to 75%, then...";
CM_ BO_ 2365166334 "ER DC/DC Converter 1 Power Limits Request";
CM_ SG_ 2365166334 ErDD1PrmrSdPwrMnmmLmtRqst "ER DC/DC 1 Primary Side Power Minimum Limit Request: The minimum allowed primary side power requested by a separate device.   Under normal conditions this requested limit would be reflected in SPN 24058 (ER DC/DC 1 Primary Side Power Minimum Limit Se...";
CM_ SG_ 2365166334 ErDD1PrmrSdPwrMxmmLmtRqst "ER DC/DC 1 Primary Side Power Maximum Limit Request: The maximum allowed primary side power requested by a separate device.   Under normal conditions this requested limit would be reflected in SPN 24059 (ER DC/DC 1 Primary Side Power Maximum Limit Se...";
CM_ SG_ 2365166334 ErDD1SndrSdPwrMnmmLmtRqst "ER DC/DC 1 Secondary Side Power Minimum Limit Request: The minimum allowed secondary side power requested by a separate device.   Under normal conditions this requested limit would be reflected in SPN 24060 (ER DC/DC 1 Secondary Side Power Minimum Li...";
CM_ SG_ 2365166334 ErDD1SndrSdPwrMxmmLmtRqst "ER DC/DC 1 Secondary Side Power Maximum Limit Request: The maximum allowed secondary side power requested by a separate device.   Under normal conditions this requested limit would be reflected in SPN 24061 (ER DC/DC 1 Secondary Side Power Maximum Li...";
CM_ BO_ 2365166590 "ER DC/DC Converter 1 Current Limits Request";
CM_ SG_ 2365166590 ErDD1PrmrSdCrrntMnmmLmtRqst "ER DC/DC 1 Primary Side Current Minimum Limit Request: The minimum (negative) allowed Primary Side current requested by a separate device.  Under normal conditions this requested limit would be reflected in SPN 24054 (ER DC/DC 1 Primary Side Current ...";
CM_ SG_ 2365166590 ErDD1PrmrSdCrrntMxmmLmtRqst "ER DC/DC 1 Primary Side Current Maximum Limit Request: The maximum allowed Primary Side current requested by a separate device.  Under normal conditions this requested limit would be reflected in SPN 24055 (ER DC/DC 1 Primary Side Current Maximum Lim...";
CM_ SG_ 2365166590 ErDD1SndrSdCrrntMnmmLmtRqst "ER DC/DC 1 Secondary Side Current Minimum Limit Request: The minimum (negative) allowed Secondary Side current requested by a separate device.   Under normal conditions this requested limit would be reflected in SPN 24056 (ER DC/DC 1 Secondary Side C...";
CM_ SG_ 2365166590 ErDD1SndrSdCrrntMxmmLmtRqst "ER DC/DC 1 Secondary Side Current Maximum Limit Request: The maximum allowed Secondary Side current requested by a separate device.   Under normal conditions this requested limit would be reflected in SPN 24057 (ER DC/DC 1 Secondary Side Current Maxi...";
CM_ BO_ 2365166846 "ER DC/DC Converter 1 Voltage Limits Request";
CM_ SG_ 2365166846 ErDD1PrmrSdVltgMnmmLmtRqst "ER DC/DC 1 Primary Side Voltage Minimum Limit Request: The minimum allowed Primary Side voltage requested by a separate device.   Under normal conditions this requested limit would be reflected in SPN 24050 (ER DC/DC 1 Primary Side Voltage Minimum Li...";
CM_ SG_ 2365166846 ErDD1PrmrSdVltgMxmmLmtRqst "ER DC/DC 1 Primary Side Voltage Maximum Limit Request: The maximum allowed Primary Side voltage requested by a separate device.   Under normal conditions this requested limit would be reflected in SPN 24051 (ER DC/DC 1 Primary Side Voltage Maximum Li...";
CM_ SG_ 2365166846 ErDD1SndrSdVltgMnmmLmtRqst "ER DC/DC 1 Secondary Side Voltage Minimum Limit Request: The minimum allowed Secondary Side voltage requested by a separate device.   Under normal conditions this requested limit would be reflected in SPN 24052 (ER DC/DC 1 Secondary Side Voltage Mini...";
CM_ SG_ 2365166846 ErDD1SndrSdVltgMxmmLmtRqst "ER DC/DC 1 Secondary Side Voltage Maximum Limit Request: The maximum allowed Secondary Side voltage requested by a separate device.   Under normal conditions this requested limit would be reflected in SPN 24053 (ER DC/DC 1 Secondary Side Voltage Maxi...";
CM_ BO_ 2365167102 "ER DC/DC Converter 1 Temperatures";
CM_ SG_ 2365167102 ErDcDc1ConverterTemperature "ER DC/DC 1 Converter Temperature: Parameter indicating the temperature of the Extended Range DC/DC Converter (e.g, controller, circuit board, enclosure).";
CM_ SG_ 2365167102 ErDD1CnvrtrEltrnFltrTmprtr "ER DC/DC 1 Converter Electronic Filter Temperature: Parameter indicating the temperature of the electronic components that make up the Extended Range DC/DC Converter filter.";
CM_ SG_ 2365167102 ErDD1PwrEltrnsTmprtr "ER DC/DC 1 Power Electronics Temperature: Parameter indicating the temperature of the Extended Range DC/DC Converter power electronics components (e.g, switch or heatsink).";
CM_ SG_ 2365167102 ErDcDc1CoolantInTemperature "ER DC/DC 1 Coolant  In Temperature: Parameter indicating the temperature of the Extended Range DC/DC Converter Coolant measured at the input of the converter";
CM_ SG_ 2365167102 ErDcDc1CoolantOutTemperature "ER DC/DC 1 Coolant Out Temperature: Parameter indicating the temperature of the Extended Range DC/DC Converter Coolant measured at the output of the converter";
CM_ BO_ 2566493950 "ER DC/DC Converter 1 Power Limit Settings";
CM_ SG_ 2566493950 ErDD1PrmrSdPwrMnmmLmtSttng "ER DC/DC 1 Primary Side Power Minimum Limit Setting: Reports the active minimum primary side power limit of the Extended Range DC/DC Converter.  The setting may be requested by a separate device (via SPN 24075 (ER DC/DC 1 Primary Side Power Minimum L...";
CM_ SG_ 2566493950 ErDD1PrmrSdPwrMxmmLmtSttng "ER DC/DC 1 Primary Side Power Maximum Limit Setting: Reports the active maximum primary side power limit of the Extended Range DC/DC Converter.  The setting may be requested by a separate device (via SPN 24076 (ER DC/DC 1 Primary Side Power Maximum L...";
CM_ SG_ 2566493950 ErDD1SndrSdPwrMnmmLmtSttng "ER DC/DC 1 Secondary Side Power Minimum Limit Setting: Reports the active minimum secondary side power limit of the Extended Range DC/DC Converter.  The setting may be requested by a separate device (via SPN 24077 (ER DC/DC 1 Secondary Side Power Min...";
CM_ SG_ 2566493950 ErDD1SndrSdPwrMxmmLmtSttng "ER DC/DC 1 Secondary Side Power Maximum Limit Setting: Reports the active maximum secondary side power limit of the Extended Range DC/DC Converter.  The setting may be requested by a separate device (via SPN 24078 (ER DC/DC 1 Secondary Side Power Max...";
CM_ BO_ 2566494206 "ER DC/DC Converter 1 Current Limits Settings";
CM_ SG_ 2566494206 ErDD1PrmrSdCrrntMnmmLmtSttng "ER DC/DC 1 Primary Side Current Minimum Limit Setting: Reports the active minimum limit (negative) on the Primary Side current of the Extended Range DC/DC Converter.  The setting may be requested by a separate device (via SPN 24071 (ER DC/DC 1 Primar...";
CM_ SG_ 2566494206 ErDD1PrmrSdCrrntMxmmLmtSttng "ER DC/DC 1 Primary Side Current Maximum Limit Setting: Reports the active maximum limit on the Primary Side current of the Extended Range DC/DC Converter.  The setting may be requested by a separate device (via SPN 24072 (ER DC/DC 1 Primary Side Curr...";
CM_ SG_ 2566494206 ErDD1SndrSdCrrntMnmmLmtSttng "ER DC/DC 1 Secondary Side Current Minimum Limit Setting: Reports the active minimum limit (negative) on the Secondary Side current of the Extended Range DC/DC Converter.  The setting may be requested by a separate device (via SPN 24073 (ER DC/DC 1 Se...";
CM_ SG_ 2566494206 ErDD1SndrSdCrrntMxmmLmtSttng "ER DC/DC 1 Secondary Side Current Maximum Limit Setting: Reports the active maximum limit on the Secondary Side current of the Extended Range DC/DC Converter.  The setting may be requested by a separate device (via SPN 24074 (ER DC/DC 1 Secondary Sid...";
CM_ BO_ 2566494462 "ER DC/DC Converter 1 Voltage Limit Settings";
CM_ SG_ 2566494462 ErDD1PrmrSdVltgMnmmLmtSttng "ER DC/DC 1 Primary Side Voltage Minimum Limit Setting: Reports the active minimum limit on the Primary Side voltage of the Extended Range DC/DC Converter.  The setting may be requested by a separate device (via SPN 24067 (ER DC/DC 1 Primary Side Volt...";
CM_ SG_ 2566494462 ErDD1PrmrSdVltgMxmmLmtSttng "ER DC/DC 1 Primary Side Voltage Maximum Limit Setting: Reports the active maximum limit on the Primary Side voltage of the Extended Range DC/DC Converter.  The setting may be requested by a separate device (via SPN 24068 (ER DC/DC 1 Primary Side Volt...";
CM_ SG_ 2566494462 ErDD1SndrSdVltgMnmmLmtSttng "ER DC/DC 1 Secondary Side Voltage Minimum Limit Setting: Reports the active minimum limit on the Secondary Side voltage of the Extended Range DC/DC Converter.  The setting may be requested by a separate device (via SPN 24069 (ER DC/DC 1 Secondary Sid...";
CM_ SG_ 2566494462 ErDD1SndrSdVltgMxmmLmtSttng "ER DC/DC 1 Secondary Side Voltage Maximum Limit Setting: Reports the active maximum limit on the Secondary Side voltage of the Extended Range DC/DC Converter.  The setting may be requested by a separate device (via SPN 24070 (ER DC/DC 1 Secondary Sid...";
CM_ BO_ 2365168126 "ER DC/DC Converter 1 Low Voltage";
CM_ SG_ 2365168126 ErDD1CntrllrInptIgntnVltg "ER DC/DC 1 Controller Input Ignition Voltage: Ignition voltage (i.e. switched) supplied to the  Extended Range DC/DC Converter controller.";
CM_ SG_ 2365168126 ErDD1CntrllrInptUnswthdSlVltg "ER DC/DC 1 Controller Input Unswitched SLI Voltage: Continuously supplied SLI power to this instance of the Extended Range DC/DC Converter controller.";
CM_ BO_ 2365168382 "ER DC/DC Converter 1 Power and Chassis Voltage";
CM_ SG_ 2365168382 ErDcDc1PrimarySidePower "ER DC/DC 1 Primary Side Power: Indicates the Primary Side power measured at the Extended Range DC/DC Converter.  The Primary Side power is positive if the converter is flowing current from the Secondary Side to the Primary side.  The Primary Side pow...";
CM_ SG_ 2365168382 ErDcDc1SecondarySidePower "ER DC/DC 1 Secondary Side Power: Indicates the Secondary Side power measured at the Extended Range DC/DC Converter.  The Secondary Side power is positive if the converter is flowing current from the Primary Side to the Secondary side.  The Secondary ...";
CM_ SG_ 2365168382 ErDD1PrmrSdNgtvTChsssGrndVltg "ER DC/DC 1 Primary Side Negative to Chassis Ground Voltage: The voltage level as measured by the ER DC/DC between the Primary Side negative ER DC bus and the chassis of the ER DC/DC enclosure.  This voltage can be used for system level monitoring of ...";
CM_ SG_ 2365168382 ErDD1SndrSdNgtvTChsssGrndVltg "ER DC/DC 1 Secondary Side Negative to Chassis Ground Voltage: The voltage level as measured by the ER DC/DC between the Secondary Side negative ER DC bus and the chassis of the ER DC/DC enclosure.  This voltage can be used for system level monitoring...";
CM_ BO_ 2365168638 "ER DC/DC Converter 1 Voltage and Current";
CM_ SG_ 2365168638 ErDcDc1PrimarySideVoltage "ER DC/DC 1 Primary Side Voltage: Indicates the measured Primary Side voltage measured at the point of control inside the Extended Range DC/DC Converter.Refer to SPN 24082 (ER DC/DC 1 Reference Voltage) to convert % to Volts.";
CM_ SG_ 2365168638 ErDcDc1SecondarySideVoltage "ER DC/DC 1 Secondary Side Voltage: Indicates the measured Secondary Side voltage measured at the point of control inside the Extended Range DC/DC Converter.Refer to SPN 24082 (ER DC/DC 1 Reference Voltage) to convert % to Volts.";
CM_ SG_ 2365168638 ErDcDc1PrimarySideCurrent "ER DC/DC 1 Primary Side Current: Indicates the measured Primary Side current measured at the point of control inside the Extended Range DC/DC Converter.  The current is positive if the converter is flowing current from the Secondary to the Primary Si...";
CM_ SG_ 2365168638 ErDcDc1SecondarySideCurrent "ER DC/DC 1 Secondary Side Current: Indicates the measured Secondary Side current measured at the point of control inside the Extended Range DC/DC Converter.  The current is positive if the converter is flowing current from the Primary to the Secondar...";
CM_ BO_ 2365168894 "ER DC/DC Converter 1 Operating Status";
CM_ SG_ 2365168894 ErDcDc1StatusCrc "ER DC/DC 1 Status CRC: The CRC is defined as follows: - Length: 8 bits- Polynomial: x^8+x^5+x^3+x^2+x+1- Initial Value: FFh- Input Data Reflection: Not reflected- Result Data Reflection: Not reflected- XOR value: FFh SAE makes no claim of the functio...";
CM_ SG_ 2365168894 ErDcDc1StatusCounter "ER DC/DC 1 Status Counter: The message counter is used to detect situations where the transmitting ECU malfunction repeats the same frame all the time. The receiver of the information may use the counter parameter to detect this situation. The transm...";
CM_ SG_ 2365168894 ErDcDc1OperationalStatus "ER DC/DC 1 Operational Status: Operating state of the Extended Range DC/DC Converter0000b = Disabled - In this mode all high voltage switching is disabled0001b = Initialization - The device is powering up.  This process may include both internal chec...";
CM_ SG_ 2365168894 ErDcDc1HvilStatus "ER DC/DC 1 HVIL Status: High Voltage Interlock Loop (HVIL) state of the Extended Range DC/DC Converter.00b = HVIL Closed01b = HVIL Open10b = Error11b = Not Available";
CM_ SG_ 2365168894 ErDcDc1LoadshedRequest "ER DC/DC 1 Loadshed Request: The loadshed request is a request to the controlling device to reduce the Extended Range DC/DC Converter loads.  The Loadshed Requested state is an indication that this Extended Range DC/DC Converter has a malfunction or ...";
CM_ SG_ 2365168894 ErDD1PwrLmtDTPrmrSdCrrntMnmm "ER DC/DC 1 Power Limit due to Primary Side Current Minimum: Indicates whether or not output power is being limited due to Primary Side current (see SPN 24042 (ER DC/DC 1 Primary Side Current)) approaching or exceeding the minimum limit (see SPN 24054...";
CM_ SG_ 2365168894 ErDD1PwrLmtDTPrmrSdCrrntMxmm "ER DC/DC 1 Power Limit due to Primary Side Current Maximum: Indicates whether or not output power is being limited due to Primary Side current (see SPN 24042 (ER DC/DC 1 Primary Side Current)) approaching or exceeding the maximum limit (see SPN 24055...";
CM_ SG_ 2365168894 ErDD1PwrLmtDTSndrSdCrrntMnmm "ER DC/DC 1 Power Limit due to Secondary Side Current Minimum: Indicates whether or not output power is being limited due to Secondary Side current (see SPN 24043 (ER DC/DC 1 Secondary Side Current)) approaching or exceeding the minimum limit (see SPN...";
CM_ SG_ 2365168894 ErDD1PwrLmtDTSndrSdCrrntMxmm "ER DC/DC 1 Power Limit due to Secondary Side Current Maximum: Indicates whether or not output power is being limited due to Secondary Side current (see SPN 24043 (ER DC/DC 1 Secondary Side Current)) approaching or exceeding the maximum limit (see SPN...";
CM_ SG_ 2365168894 ErDD1PwrLmtDTPrmrSdVltgMnmm "ER DC/DC 1 Power Limit due to Primary Side Voltage Minimum: Indicates whether or not output power is being limited due to Primary Side voltage (see SPN 24040 (ER DC/DC 1 Primary Side Voltage)) approaching or exceeding the minimum limit (see SPN 24050...";
CM_ SG_ 2365168894 ErDD1PwrLmtDTPrmrSdVltgMxmm "ER DC/DC 1 Power Limit due to Primary Side Voltage Maximum: Indicates whether or not output power is being limited due to Primary Side voltage (see SPN 24040 (ER DC/DC 1 Primary Side Voltage)) approaching or exceeding the maximum limit (see SPN 24051...";
CM_ SG_ 2365168894 ErDD1PwrLmtDTSndrSdVltgMnmm "ER DC/DC 1 Power Limit due to Secondary Side Voltage Minimum: Indicates whether or not output power is being limited due to Secondary Side voltage (see SPN 24041 (ER DC/DC 1 Secondary Side Voltage)) approaching or exceeding the minimum limit (see SPN...";
CM_ SG_ 2365168894 ErDD1PwrLmtDTSndrSdVltgMxmm "ER DC/DC 1 Power Limit due to Secondary Side Voltage Maximum: Indicates whether or not output power is being limited due to Secondary Side voltage (see SPN 24041 (ER DC/DC 1 Secondary Side Voltage)) approaching or exceeding the maximum limit (see SPN...";
CM_ SG_ 2365168894 ErDD1PwrLmtDTCnvrtrTmprtr "ER DC/DC 1 Power Limit due to Converter Temperature: Indicates whether or not output power is being limited due to Converter Temperature (see SPN 24062 (ER DC/DC 1 Converter Temperature)) approaching or exceeding the maximum limit.00b = No power limi...";
CM_ SG_ 2365168894 ErDD1PwrLmtDTEltrnFltrTmprtr "ER DC/DC 1 Power Limit due to Electronic Filter Temperature: Indicates whether or not output power is being limited due to Output Electronic Filter Temperature (see SPN 24063 (ER DC/DC 1 Converter Electronic Filter Temperature)) approaching or exceed...";
CM_ SG_ 2365168894 ErDD1PwrLmtDTPwrEltrnsTmprtr "ER DC/DC 1 Power Limit due to Power Electronics Temperature: Indicates whether or not output power is being limited due to Power Electronics Temperature (see SPN 24064 (ER DC/DC 1 Power Electronics Temperature)) approaching or exceeding the maximum l...";
CM_ SG_ 2365168894 ErDD1PwrLmtDTUndfndRsn "ER DC/DC 1 Power Limit due to Undefined Reason: Indicates whether or not output power is being limited due to an undefined reason.00b = No power limit for this reason01b = Power limited for this reason10b = Error11b = Not Available";
CM_ BO_ 2365169150 "ER DC/DC Converter 1 Control";
CM_ SG_ 2365169150 ErDcDc1CommandCrc "ER DC/DC 1 Command CRC: The CRC is defined as follows: - Length: 8 bits- Polynomial: x^8+x^5+x^3+x^2+x+1- Initial Value: FFh- Input Data Reflection: Not reflected- Result Data Reflection: Not reflected- XOR value: FFh SAE makes no claim of the functi...";
CM_ SG_ 2365169150 ErDcDc1CommandCounter "ER DC/DC 1 Command  Counter: The message counter is used to detect situations where the transmitting ECU malfunction repeats the same frame all the time. The receiver of the information may use the counter parameter to detect this situation. The tran...";
CM_ SG_ 2365169150 ErDcDc1OperationalCommand "ER DC/DC 1 Operational Command: Command to enable or disable operation.0000b = Disable - in this mode all high voltage switching is disabled0001b = Standby - system is ready and waiting for command to enter control modes0010b = Power Down - stop all ...";
CM_ SG_ 2365169150 ErDcDc1OperationalSetpoint "ER DC/DC 1 Operational Setpoint: The set point for regulating the DC/DC Converter per SPN 24021 (ER DC/DC 1 Operational Command).  When in Voltage control modes (states 0100b and 0101b of SPN 24021 (ER DC/DC 1 Operational Command)), the operational r...";
CM_ BO_ 2566495998 "Cab Air Quality System Information 2";
CM_ SG_ 2566495998 CabCo2ConcentrationStatus "Cab CO2 Concentration Status: Indicates the status of CO2 concentration in the cab.000b = High Most severe 001b = High Least severe 010b = In Range 011b = Low Least severe 100b = Low Most severe 101b = Reserved110b = Error 111b = Not available...";
CM_ SG_ 2566495998 CabPressureStatus "Cab Pressure Status: Indicates the status of the gauge pressure in the cab.000b = High Most severe 001b = High Least severe 010b = In Range 011b = Low Least severe 100b = Low Most severe 101b = Reserved110b = Error 111b = Not available";
CM_ SG_ 2566495998 CabDustConcentrationStatus "Cab Dust Concentration Status: Indicates the status of dust concentration in the cab.000b = High Most severe 001b = High Least severe 010b = In Range 011b = Low Least severe 100b = Low Most severe 101b = Reserved110b = Error 111b = Not available...";
CM_ BO_ 2566496254 "Cab Air Quality System Information 1";
CM_ SG_ 2566496254 CabCo2Concentration "Cab CO2 Concentration: The CO2 concentration measured inside the cab.";
CM_ SG_ 2566496254 CabPressure "Cab Pressure: The gauge pressure in the cab. Negative values indicate a vacuum in the cab.";
CM_ SG_ 2566496254 CabDustConcentration "Cab Dust Concentration: The dust concentration measured inside the cab.";
CM_ SG_ 2566496254 CabPressureSensorStatus "Cab Pressure Sensor Status: Indicates that the cab gauge pressure reading of sensor is normal as determined by the manufacturer's control software.This sensor is located in the operator cab.00b = OK (Pressure Normal)01b = Not OK (Pressure Out of oper...";
CM_ SG_ 2566496254 CabCo2ConcentrationSensorStatus "Cab CO2 Concentration Sensor Status: Indicates that the cab CO2 concentration reading of sensor is normal as determined by the manufacturer's control software.This sensor is located in the operator cab.00b = OK (CO2 Concentration measurement Normal) ...";
CM_ SG_ 2566496254 CDstCnntrtnSnsrStts "Cab Dust Concentration Sensor Status: Indicates that the cab dust concentration reading of sensor is normal as determined by the manufacturer's control software.This sensor is located in the operator cab. 00b = OK (Dust Concentration measurement Norm...";
CM_ BO_ 2566496510 "Well Stimulation Pump System 6";
CM_ SG_ 2566496510 AtWSttPpLOFwRtExtddR "Actual Well Stimulation Pump Lube Oil Flow Rate (Extended Range): Estimated flow rate of the well stimulation pump lube oil in the lubrication circuit. For example, lube oil flow rate may be calculated based on the oil viscosity, temperature, and pre...";
CM_ SG_ 2566496510 EsttdWSttPpLOFwRtExtddR "Estimated Well Stimulation Pump Lube Oil Flow Rate (Extended Range): Actual flow rate of the well stimulation pump lube oil in the lubrication circuit.";
CM_ SG_ 2566496510 AtWSttPpGBxLOFwRtExtddR "Actual Well Stimulation Pump Gear Box Lube Oil Flow Rate (Extended Range): Estimated flow rate of the well stimulation pump lube oil in the gear box lubrication circuit. For example, lube oil flow rate may be calculated based on the oil viscosity, te...";
CM_ SG_ 2566496510 EsttdWSttPpGBxLOFwRtExtddR "Estimated Well Stimulation Pump Gear Box Lube Oil Flow Rate (Extended Range): Actual flow rate of the well stimulation pump lube oil in the gear box lubrication circuit.";
CM_ BO_ 2566496766 "Engine Fuel/Lube Systems 4";
CM_ SG_ 2566496766 EngnFlInjtnSstmDsrdOlPmpMtrSpd "Engine Fuel Injection System Desired Oil Pump Motor Speed: Indicates the desired oil pump motor speed of the fuel injection system.";
CM_ SG_ 2566496766 EngnFlInjtnSstmOlRl1Prssr "Engine Fuel Injection System Oil Rail 1 Pressure: The gage pressure of the oil rail used for the fuel injection system.";
CM_ SG_ 2566496766 EngnFlInjtnSstmOlRl2Prssr "Engine Fuel Injection System Oil Rail 2 Pressure: The gage pressure of the oil rail 2 used for the fuel injection system.";
CM_ SG_ 2566496766 EFItSstOPpFwCtVvCd "Engine Fuel Injection System Oil Pump Flow Control Valve Command: Indicates the commanded position of oil pump flow valve which controls the fuel injection system. 0% indicates no flow through valve and 100% means maximum flow through the valve.";
CM_ SG_ 2566496766 EFItSstOPssLttVvCd "Engine Fuel Injection System Oil Pressure Limitation Valve Command: Indicates the device controlling the valve limiting the maximum oil rail pressure in the fuel injection system. When closed, the valve is limiting flow through the valve resulting in...";
CM_ SG_ 2566496766 EngnFlInjtnSstmOlPmpMtrEnlCmmnd "Engine Fuel Injection System Oil Pump Motor Enable Command: Indicates the enable command to power on/off the oil pump motor of the fuel injection system.00b = Off01b = On10b = Reserved11b = Not Supported";
CM_ BO_ 2566497022 "Alternate Fuel 6";
CM_ SG_ 2566497022 EF2ItMtR1PssExtddR "Engine Fuel 2 Injector Metering Rail 1 Pressure  (Extended Range): The pressure of fuel 2 measured by rail pressure sensor in the metering rail as delivered from the supply pump to the injector metering intake.  NOTE - See SPN 7021 for alternate reso...";
CM_ SG_ 2566497022 EF2ItMtR2PssExtddR "Engine Fuel 2 Injector Metering Rail 2 Pressure  (Extended Range): The pressure of fuel 2 measured by rail pressure sensor in the metering rail 2 as delivered from the supply pump to the injector metering intake.  NOTE - See SPN 7022 for alternate re...";
CM_ SG_ 2566497022 EngnFl2DsrdPmpMtrSpd "Engine Fuel 2 Desired Pump Motor Speed: Desired motor speed of the pump  for the second fuel type.";
CM_ SG_ 2566497022 EngnFl2PmpMtrEnlCmmnd "Engine Fuel 2 Pump Motor Enable Command: Indicates the enable command to power on/off the pump motor for the second fuel type.00b = Off01b = On10b = Reserved11b = Not Supported";
CM_ SG_ 2566497022 EngnFl2PmpBpssVlvCmmnd "Engine Fuel 2 Pump Bypass Valve Command: Indicates the command to open/close the pump bypass valve for the second fuel type. When open, the value fully diverts fuel flow from the pump.  When closed, no flow through the bypass valve.00b = Open01b = Cl...";
CM_ BO_ 2566497278 "Engine Catalyst Diverter Actuator Control";
CM_ SG_ 2566497278 EngnCtlstDvrtrAttr1Cmmnd "Engine Catalyst Diverter Actuator 1 Command: The control command to the first catalyst diverter actuator on an engine. 100% represents the valve is commanded to allow flow to completely bypass the catalyst and 0% represents the flow is fully through ...";
CM_ SG_ 2566497278 EngnCtlstDvrtrAttr2Cmmnd "Engine Catalyst Diverter Actuator 2 Command: The control command to the second catalyst diverter actuator on an engine. 100% represents the valve is commanded to allow flow to completely bypass the catalyst and 0% represents the flow is fully through...";
CM_ BO_ 2566497534 "Ambient Conditions 4";
CM_ SG_ 2566497534 FuelSpecificHumidity "Fuel Specific Humidity: Specific humidity of the fuel.";
CM_ SG_ 2566497534 EngineChargeAirSpecificHumidity "Engine Charge Air Specific Humidity: Specific humidity of the charge air";
CM_ SG_ 2566497534 FuelRelativeHumidity "Fuel Relative Humidity: Relative humidity of the fuel.";
CM_ SG_ 2566497534 EngineChargeAirRelativeHumidity "Engine Charge Air Relative Humidity: Relative humidity of the charge air.";
CM_ BO_ 2566497790 "Engine Exhaust Particulate Control System Info 2";
CM_ SG_ 2566497790 Atttt2ExstPttCtSstDstT "Aftertreatment 2 Exhaust Particulate Control System Diagnostic Time: The total time aftertreatment 2 exhaust particulate control diagnostic codes have been active. Total time only includes the active time for codes which have been active above a pred...";
CM_ SG_ 2566497790 Atttt2ExstPttCtSstDstCt "Aftertreatment 2 Exhaust Particulate Control System Diagnostic Count: The total occurrences of diagnostic codes for the aftertreatment 2 exhaust particulate control system that have been active above a predetermined time threshold. A code that has be...";
CM_ BO_ 2566498046 "Engine Exhaust Particulate Control System Info 1";
CM_ SG_ 2566498046 Atttt1ExstPttCtSstDstT "Aftertreatment 1 Exhaust Particulate Control System Diagnostic Time: The total time the first aftertreatment exhaust particulate control diagnostic codes have been active. Total time only includes the active time for codes which have been active abov...";
CM_ SG_ 2566498046 Atttt1ExstPttCtSstDstCt "Aftertreatment 1 Exhaust Particulate Control System Diagnostic Count: The total occurrences of diagnostic codes for the first aftertreatment exhaust particulate control system that have been active above a predetermined time threshold. A code that ha...";
CM_ BO_ 2566498302 "Aftertreatment System Information 20";
CM_ SG_ 2566498302 Atttt2TtERtWtNDsExstFdDv "Aftertreatment 2 Total Engine Runtime With No Diesel Exhaust Fluid Delivery: Aftertreatment 2 total engine run time with no delivery of reductant (e.g., diesel exhaust fluid) used to control NOx emissions due to insufficient exhaust temperature.";
CM_ SG_ 2566498302 Atttt2TtEvtCtWtNDsExstFdDv "Aftertreatment 2 Total Event Count With No Diesel Exhaust Fluid Delivery: The total occurrences of diagnostic code for the Aftertreatment 2 With No DEF Delivery that have been active above a predetermined time threshold. A bucket that has been active...";
CM_ BO_ 2566498558 "Aftertreatment System Information 19";
CM_ SG_ 2566498558 Aftrtrtmnt2SrIntkHghTmprtrTm "Aftertreatment 2 SCR Intake High Temperature Time: Indicates the time the aftertreatment 2 SCR intake temperature is above a manufacturer specified threshold. This is the temperature of engine combustion byproducts entering the SCR in exhaust bank 2....";
CM_ SG_ 2566498558 Aftrtrtmnt2SrIntkHghTmprtrCnt "Aftertreatment 2 SCR Intake High Temperature Count: The total occurrences of diagnostic code for the Aftertreatment 2 SCR Intake High Temperature. This parameter will accumulate over the life of the product and will never be reset. (Reference EU Comm...";
CM_ BO_ 2566498814 "Aftertreatment System Information 18";
CM_ SG_ 2566498814 Aftrtrtmnt2DslExhstFldFrznTm "Aftertreatment 2 Diesel Exhaust Fluid Frozen Time: Indicates the amount of time the aftertreatment 2 diesel exhaust fluid is frozen while key switch is on. This will accumulate over the life of the product, and will never be reset. This parameter is ...";
CM_ SG_ 2566498814 Aftrtrtmnt2DslExhstFldFrznCnt "Aftertreatment 2 Diesel Exhaust Fluid Frozen Count: The total occurrences of diagnostic code for Aftertreatment 2 Diesel Exhaust Fluid Frozen. This parameter will accumulate over the life of the product and will never be reset. (Reference EU Commissi...";
CM_ BO_ 2566499070 "Aftertreatment System Information 17";
CM_ SG_ 2566499070 Aftrtrtmnt2SrMlfntnTm "Aftertreatment 2 SCR Malfunction Time: Indicates the amount of time an error condition has been active due to a malfunction in the Aftertreatment 2 SCR system. The source of the malfunction condition could be a component failure, detection of tamperi...";
CM_ SG_ 2566499070 Aftrtrtmnt2SrMlfntnCnt "Aftertreatment 2 SCR Malfunction Count: The total occurrences of diagnostic code for the Aftertreatment 2 SCR Malfunction that have been active above a predetermined time threshold. A bucket that has been active less than the predetermined time thres...";
CM_ BO_ 2566499326 "Aftertreatment System Information 16";
CM_ SG_ 2566499326 Atttt2DsExstFdQtMtT "Aftertreatment 2 Diesel Exhaust Fluid Quality Malfunction Time: Indicates the amount of time an error has been active due to detection of low Diesel Exhaust Fluid Quality on Aftertreatment 2. This will accumulate over the life of the product and will...";
CM_ SG_ 2566499326 Atttt2DsExstFdQtMtCt "Aftertreatment 2 Diesel Exhaust Fluid Quality Malfunction Count: The total occurrences of diagnostic code for the Aftertreatment 2 Diesel Exhaust Fluid Quality Malfunction that have been active above a predetermined time threshold. A bucket that has ...";
CM_ BO_ 2566499582 "Aftertreatment System Information 15";
CM_ SG_ 2566499582 Atttt2DsExstFdT1EptT "Aftertreatment 2 Diesel Exhaust Fluid Tank 1 Empty Time: Indicates the time the Aftertreatment 2 Diesel Exhaust Fluid Tank 1 Level is indicated as empty. This will accumulate over the life of the product and will never be reset.";
CM_ SG_ 2566499582 Atttt2DsExstFdT1EptCt "Aftertreatment 2 Diesel Exhaust Fluid Tank 1 Empty Count: The total occurrences of diagnostic code for the Aftertreatment 2 Diesel Exhaust Fluid Tank 1 Empty. This parameter will accumulate over the life of the product and will never be reset.";
CM_ BO_ 2566499838 "Aftertreatment System Information 14";
CM_ SG_ 2566499838 AttttTtERtWtNDsExstFdDv "Aftertreatment Total Engine Runtime With No Diesel Exhaust Fluid Delivery: Aftertreatment total engine run time with no delivery of reductant (e.g., diesel exhaust fluid) used to control NOx emissions due to insufficient exhaust temperature.";
CM_ SG_ 2566499838 AttttTtEvtCtWtNDsExstFdDv "Aftertreatment Total Event Count With No Diesel Exhaust Fluid Delivery: The total occurrences of diagnostic code for the Aftertreatment With No DEF Delivery that have been active above a predetermined time threshold. A bucket that has been active les...";
CM_ BO_ 2566500094 "Aftertreatment System Information 13";
CM_ SG_ 2566500094 AftrtrtmntSrIntkHghTmprtrTm "Aftertreatment SCR Intake High Temperature Time: Indicates the time the aftertreatment SCR intake temperature is above a manufacturer specified threshold. This is the temperature of engine combustion byproducts entering the SCR exhaust bank. On dual ...";
CM_ SG_ 2566500094 AftrtrtmntSrIntkHghTmprtrCnt "Aftertreatment SCR Intake High Temperature Count: The total occurrences of diagnostic code for all Aftertreatment SCR Intake High Temperature. For dual SCR catalyst systems this would include aftertreatment 1 and aftertreatment 2 SCR Intake High Temp...";
CM_ BO_ 2566500350 "Aftertreatment System Information 12";
CM_ SG_ 2566500350 Aftrtrtmnt1DslExhstFldFrznTm "Aftertreatment 1 Diesel Exhaust Fluid Frozen Time: Indicates the amount of time the first aftertreatment diesel exhaust fluid is frozen while key switch is on. This will accumulate over the life of the product, and will never be reset. This parameter...";
CM_ SG_ 2566500350 Aftrtrtmnt1DslExhstFldFrznCnt "Aftertreatment 1 Diesel Exhaust Fluid Frozen Count: The total occurrences of diagnostic code for the first aftertreatment Diesel Exhaust Fluid Frozen. This parameter will accumulate over the life of the product and will never be reset. (Reference EU ...";
CM_ BO_ 2566500606 "Aftertreatment System Information 11";
CM_ SG_ 2566500606 Aftrtrtmnt1SrMlfntnTm "Aftertreatment 1 SCR Malfunction Time: Indicates the amount of time an error condition has been active due to a malfunction in the first Aftertreatment SCR system. The source of the malfunction condition could be a component failure, detection of tam...";
CM_ SG_ 2566500606 Aftrtrtmnt1SrMlfntnCnt "Aftertreatment 1 SCR Malfunction Count: The total occurrences of diagnostic code for the first Aftertreatment SCR Malfunction that have been active above a predetermined time threshold. A bucket that has been active less than the predetermined time t...";
CM_ BO_ 2566500862 "Aftertreatment System Information 10";
CM_ SG_ 2566500862 Atttt1DsExstFdQtMtT "Aftertreatment 1 Diesel Exhaust Fluid Quality Malfunction Time: Indicates the amount of time an error has been active due to detection of the first aftertreatment low Diesel Exhaust Fluid Quality. This will accumulate over the life of the product and...";
CM_ SG_ 2566500862 Atttt1DsExstFdQtMtCt "Aftertreatment 1 Diesel Exhaust Fluid Quality Malfunction Count: The total occurrences of diagnostic code for the first aftertreatment Diesel Exhaust Fluid Quality Malfunction that have been active above a predetermined time threshold. A bucket that ...";
CM_ BO_ 2566501118 "Aftertreatment System Information 9";
CM_ SG_ 2566501118 Atttt1DsExstFdT1EptT "Aftertreatment 1 Diesel Exhaust Fluid Tank 1 Empty Time: Indicates the time the first aftertreatment Diesel Exhaust Fluid Tank 1 Level is indicated as empty. This will accumulate over the life of the product and will never be reset.";
CM_ SG_ 2566501118 Atttt1DsExstFdT1EptCt "Aftertreatment 1 Diesel Exhaust Fluid Tank 1 Empty Count: The total occurrences of diagnostic code for the first aftertreatment Diesel Exhaust Fluid Tank 1 Empty. This parameter will accumulate over the life of the product and will never be reset.";
CM_ BO_ 2499392766 "Genset Supporting Functions 2";
CM_ SG_ 2499392766 SmltdMnsFrqnOffstExtnddRng "Simulated Mains Frequency Offset (Extended Range): Simulated mains frequency offset for test functionality for grid code functions. The simulated frequency offset can be added to the measured frequency or to the nominal frequency.  This SPN allows fo...";
CM_ BO_ 2566501886 "Alternator Information 2";
CM_ SG_ 2566501886 AltrntrStpntVltgFdk "Alternator Setpoint Voltage Feedback: The alternator output voltage feedback with respect to SPN 7589.";
CM_ SG_ 2566501886 AlternatorOutputVoltage "Alternator Output Voltage: The alternator output voltage provided in response to SPN 7589.";
CM_ SG_ 2566501886 AltrntrVltgRgltrTmprtr "Alternator Voltage Regulator Temperature: The temperature measured at the voltage regulator inside the alternator.";
CM_ SG_ 2566501886 AlternatorExcitationCurrent "Alternator Excitation Current: The current measured through the excitation coil in the alternator.";
CM_ SG_ 2566501886 AlternatorExcitationDutyCycle "Alternator Excitation Duty Cycle: The duty cycle used to control alternator output with the excitation coil.";
CM_ BO_ 2499417598 "Genset Supporting Functions";
CM_ SG_ 2499417598 RtvPwrRmtInptCmpnstnFtr "Reactive Power Remote Input Compensation Factor: Remote input compensation factor to a rated generator reactive power represented as a percentage.";
CM_ SG_ 2499417598 RlPwrRmtInptCmpnstnFtr "Real Power Remote Input Compensation Factor: Remote input compensation factor to a rated generator real power represented as a percentage.";
CM_ BO_ 2163828734 "Alternate Fuel 7";
CM_ SG_ 2163828734 EngineFuel2DeliveryPressure "Engine Fuel 2 Delivery Pressure: Gage pressure of the second fuel in a system as delivered from supply pump.";
CM_ SG_ 2163828734 EngnFl2FltrDffrntlPrssr "Engine Fuel 2 Filter Differential Pressure: Change in the second fuel delivery pressure, measured across the filter, due to accumulation of solid or semisolid matter on the filter element.";
CM_ SG_ 2163828734 EngnFl2DlvrAsltPrssr "Engine Fuel 2 Delivery Absolute Pressure: Absolute pressure of the second fuel in system as delivered from supply pump.";
CM_ SG_ 2163828734 EngnFltrdFl2DlvrPrssr "Engine Filtered Fuel 2 Delivery Pressure: Gage pressure of the second fuel in a system as delivered from supply pump after the pressure side fuel filter.";
CM_ SG_ 2163828734 EngnFltrdFl2DlvrAsltPrssr "Engine Filtered Fuel 2 Delivery Absolute Pressure: Absolute pressure of the second fuel in a system as delivered from supply pump after the pressure side fuel filter.";
CM_ SG_ 2163828734 EngnFl2RltvDltrt1 "Engine Fuel 2 Relative Dielectricity 1: The first relative dielectricity measurement of the second fuel used to describe the engine fuel quality.";
CM_ SG_ 2163828734 EngnFl2RltvDltrt2 "Engine Fuel 2 Relative Dielectricity 2: The second relative dielectricity measurement of the second fuel used to describe the engine fuel quality.";
CM_ BO_ 2566482174 "Engine Catalyst Diverter Actuator Information";
CM_ SG_ 2566482174 EngnCtlstDvrtrAttr1Pstn "Engine Catalyst Diverter Actuator 1 Position: The position of the first catalyst diverter actuator on an engine. 100% represents the valve position allows flow to completely bypass the catalyst and 0% represents the position of the valve flow is full...";
CM_ SG_ 2566482174 EngnCtlstDvrtrAttr2Pstn "Engine Catalyst Diverter Actuator 2 Position: The position of the second catalyst diverter actuator on an engine. 100% represents the valve position allows flow to completely bypass the catalyst and 0% represents the position of the valve flow is ful...";
CM_ BO_ 2566482430 "Electronic Logging Device Hours of Service";
CM_ SG_ 2566482430 EldHsPrplsnSstmPwrStts "ELD HOS Propulsion System Power Status: Indicates the power status of the propulsion system as described in 4.3.1.1. Engine Power Status of the document referenced in the PG Description.00b = Not active 01b = Active10b = Error11b = Not Available";
CM_ SG_ 2566482430 EldHosVehicleMotionStatus "ELD HOS Vehicle Motion Status: Indicates the vehicle motion status as described in 4.3.1.2. Vehicle Motion Status of the document referenced in the PG Description.00b = Not in motion01b = In motion10b = Error11b = Not Available";
CM_ SG_ 2566482430 EldHosVehicleDistance "ELD HOS Vehicle Distance: Vehicle distance based on DOT ELD requirements as described in 4.3.1.3. Vehicle Miles of the document referenced in the PG Description.";
CM_ SG_ 2566482430 EldHosEngineHours "ELD HOS Engine Hours: Engine Hours based on DOT ELD requirements as described in 4.3.1.4. Engine Hours of the document referenced in the PG Description.This SP provides the Engine hours as defined by DOT ELD requirements but based on the OEM integrat...";
BA_DEF_ SG_  "SPN" INT 0 524287;
BA_DEF_ BO_  "VFrameFormat" ENUM  "StandardCAN","ExtendedCAN","reserved","J1939PG";
BA_DEF_DEF_  "SPN" 0;
BA_DEF_DEF_  "VFrameFormat" "J1939PG";
BA_ "SPN" SG_ 2365162494 ErDcDc3CommandCrc 24149;
BA_ "SPN" SG_ 2365162494 ErDcDc3CommandCounter 24150;
BA_ "SPN" SG_ 2365162494 ErDcDc3OperationalCommand 24151;
BA_ "SPN" SG_ 2365162494 ErDcDc3OperationalSetpoint 24152;
BA_ "SPN" SG_ 2365162750 ErDcDc2ReferenceCrc 24144;
BA_ "SPN" SG_ 2365162750 ErDcDc2ReferenceCounter 24145;
BA_ "SPN" SG_ 2365162750 ErDcDc2ReferenceCurrent 24146;
BA_ "SPN" SG_ 2365162750 ErDcDc2ReferenceVoltage 24147;
BA_ "SPN" SG_ 2365162750 ErDcDc2ReferencePower 24148;
BA_ "SPN" SG_ 2365163006 ErDD2PrmrSdPwrMnmmLmtRqst 24140;
BA_ "SPN" SG_ 2365163006 ErDD2PrmrSdPwrMxmmLmtRqst 24141;
BA_ "SPN" SG_ 2365163006 ErDD2SndrSdPwrMnmmLmtRqst 24142;
BA_ "SPN" SG_ 2365163006 ErDD2SndrSdPwrMxmmLmtRqst 24143;
BA_ "SPN" SG_ 2365163262 ErDD2PrmrSdCrrntMnmmLmtRqst 24136;
BA_ "SPN" SG_ 2365163262 ErDD2PrmrSdCrrntMxmmLmtRqst 24137;
BA_ "SPN" SG_ 2365163262 ErDD2SndrSdCrrntMnmmLmtRqst 24138;
BA_ "SPN" SG_ 2365163262 ErDD2SndrSdCrrntMxmmLmtRqst 24139;
BA_ "SPN" SG_ 2365163518 ErDD2PrmrSdVltgMnmmLmtRqst 24132;
BA_ "SPN" SG_ 2365163518 ErDD2PrmrSdVltgMxmmLmtRqst 24133;
BA_ "SPN" SG_ 2365163518 ErDD2SndrSdVltgMnmmLmtRqst 24134;
BA_ "SPN" SG_ 2365163518 ErDD2SndrSdVltgMxmmLmtRqst 24135;
BA_ "SPN" SG_ 2365163774 ErDcDc2ConverterTemperature 24127;
BA_ "SPN" SG_ 2365163774 ErDD2CnvrtrEltrnFltrTmprtr 24128;
BA_ "SPN" SG_ 2365163774 ErDD2PwrEltrnsTmprtr 24129;
BA_ "SPN" SG_ 2365163774 ErDcDc2CoolantInTemperature 24130;
BA_ "SPN" SG_ 2365163774 ErDcDc2CoolantOutTemperature 24131;
BA_ "SPN" SG_ 2566490622 ErDD2PrmrSdPwrMnmmLmtSttng 24123;
BA_ "SPN" SG_ 2566490622 ErDD2PrmrSdPwrMxmmLmtSttng 24124;
BA_ "SPN" SG_ 2566490622 ErDD2SndrSdPwrMnmmLmtSttng 24125;
BA_ "SPN" SG_ 2566490622 ErDD2SndrSdPwrMxmmLmtSttng 24126;
BA_ "SPN" SG_ 2566490878 ErDD2PrmrSdCrrntMnmmLmtSttng 24119;
BA_ "SPN" SG_ 2566490878 ErDD2PrmrSdCrrntMxmmLmtSttng 24120;
BA_ "SPN" SG_ 2566490878 ErDD2SndrSdCrrntMnmmLmtSttng 24121;
BA_ "SPN" SG_ 2566490878 ErDD2SndrSdCrrntMxmmLmtSttng 24122;
BA_ "SPN" SG_ 2566491134 ErDD2PrmrSdVltgMnmmLmtSttng 24115;
BA_ "SPN" SG_ 2566491134 ErDD2PrmrSdVltgMxmmLmtSttng 24116;
BA_ "SPN" SG_ 2566491134 ErDD2SndrSdVltgMnmmLmtSttng 24117;
BA_ "SPN" SG_ 2566491134 ErDD2SndrSdVltgMxmmLmtSttng 24118;
BA_ "SPN" SG_ 2365164798 ErDD2CntrllrInptIgntnVltg 24113;
BA_ "SPN" SG_ 2365164798 ErDD2CntrllrInptUnswthdSlVltg 24114;
BA_ "SPN" SG_ 2365165054 ErDcDc2PrimarySidePower 24109;
BA_ "SPN" SG_ 2365165054 ErDcDc2SecondarySidePower 24110;
BA_ "SPN" SG_ 2365165054 ErDD2PrmrSdNgtvTChsssGrndVltg 24111;
BA_ "SPN" SG_ 2365165054 ErDD2SndrSdNgtvTChsssGrndVltg 24112;
BA_ "SPN" SG_ 2365165310 ErDcDc2PrimarySideVoltage 24105;
BA_ "SPN" SG_ 2365165310 ErDcDc2SecondarySideVoltage 24106;
BA_ "SPN" SG_ 2365165310 ErDcDc2PrimarySideCurrent 24107;
BA_ "SPN" SG_ 2365165310 ErDcDc2SecondarySideCurrent 24108;
BA_ "SPN" SG_ 2365165566 ErDcDc2StatusCrc 24088;
BA_ "SPN" SG_ 2365165566 ErDcDc2StatusCounter 24089;
BA_ "SPN" SG_ 2365165566 ErDcDc2OperationalStatus 24090;
BA_ "SPN" SG_ 2365165566 ErDcDc2HvilStatus 24091;
BA_ "SPN" SG_ 2365165566 ErDcDc2LoadshedRequest 24092;
BA_ "SPN" SG_ 2365165566 ErDD2PwrLmtDTPrmrSdCrrntMnmm 24093;
BA_ "SPN" SG_ 2365165566 ErDD2PwrLmtDTPrmrSdCrrntMxmm 24094;
BA_ "SPN" SG_ 2365165566 ErDD2PwrLmtDTSndrSdCrrntMnmm 24095;
BA_ "SPN" SG_ 2365165566 ErDD2PwrLmtDTSndrSdCrrntMxmm 24096;
BA_ "SPN" SG_ 2365165566 ErDD2PwrLmtDTPrmrSdVltgMnmm 24097;
BA_ "SPN" SG_ 2365165566 ErDD2PwrLmtDTPrmrSdVltgMxmm 24098;
BA_ "SPN" SG_ 2365165566 ErDD2PwrLmtDTSndrSdVltgMnmm 24099;
BA_ "SPN" SG_ 2365165566 ErDD2PwrLmtDTSndrSdVltgMxmm 24100;
BA_ "SPN" SG_ 2365165566 ErDD2PwrLmtDTCnvrtrTmprtr 24101;
BA_ "SPN" SG_ 2365165566 ErDD2PwrLmtDTEltrnFltrTmprtr 24102;
BA_ "SPN" SG_ 2365165566 ErDD2PwrLmtDTPwrEltrnsTmprtr 24103;
BA_ "SPN" SG_ 2365165566 ErDD2PwrLmtDTUndfndRsn 24104;
BA_ "SPN" SG_ 2365165822 ErDcDc2CommandCrc 24084;
BA_ "SPN" SG_ 2365165822 ErDcDc2CommandCounter 24085;
BA_ "SPN" SG_ 2365165822 ErDcDc2OperationalCommand 24086;
BA_ "SPN" SG_ 2365165822 ErDcDc2OperationalSetpoint 24087;
BA_ "SPN" SG_ 2365166078 ErDcDc1ReferenceCrc 24079;
BA_ "SPN" SG_ 2365166078 ErDcDc1ReferenceCounter 24080;
BA_ "SPN" SG_ 2365166078 ErDcDc1ReferenceCurrent 24081;
BA_ "SPN" SG_ 2365166078 ErDcDc1ReferenceVoltage 24082;
BA_ "SPN" SG_ 2365166078 ErDcDc1ReferencePower 24083;
BA_ "SPN" SG_ 2365166334 ErDD1PrmrSdPwrMnmmLmtRqst 24075;
BA_ "SPN" SG_ 2365166334 ErDD1PrmrSdPwrMxmmLmtRqst 24076;
BA_ "SPN" SG_ 2365166334 ErDD1SndrSdPwrMnmmLmtRqst 24077;
BA_ "SPN" SG_ 2365166334 ErDD1SndrSdPwrMxmmLmtRqst 24078;
BA_ "SPN" SG_ 2365166590 ErDD1PrmrSdCrrntMnmmLmtRqst 24071;
BA_ "SPN" SG_ 2365166590 ErDD1PrmrSdCrrntMxmmLmtRqst 24072;
BA_ "SPN" SG_ 2365166590 ErDD1SndrSdCrrntMnmmLmtRqst 24073;
BA_ "SPN" SG_ 2365166590 ErDD1SndrSdCrrntMxmmLmtRqst 24074;
BA_ "SPN" SG_ 2365166846 ErDD1PrmrSdVltgMnmmLmtRqst 24067;
BA_ "SPN" SG_ 2365166846 ErDD1PrmrSdVltgMxmmLmtRqst 24068;
BA_ "SPN" SG_ 2365166846 ErDD1SndrSdVltgMnmmLmtRqst 24069;
BA_ "SPN" SG_ 2365166846 ErDD1SndrSdVltgMxmmLmtRqst 24070;
BA_ "SPN" SG_ 2365167102 ErDcDc1ConverterTemperature 24062;
BA_ "SPN" SG_ 2365167102 ErDD1CnvrtrEltrnFltrTmprtr 24063;
BA_ "SPN" SG_ 2365167102 ErDD1PwrEltrnsTmprtr 24064;
BA_ "SPN" SG_ 2365167102 ErDcDc1CoolantInTemperature 24065;
BA_ "SPN" SG_ 2365167102 ErDcDc1CoolantOutTemperature 24066;
BA_ "SPN" SG_ 2566493950 ErDD1PrmrSdPwrMnmmLmtSttng 24058;
BA_ "SPN" SG_ 2566493950 ErDD1PrmrSdPwrMxmmLmtSttng 24059;
BA_ "SPN" SG_ 2566493950 ErDD1SndrSdPwrMnmmLmtSttng 24060;
BA_ "SPN" SG_ 2566493950 ErDD1SndrSdPwrMxmmLmtSttng 24061;
BA_ "SPN" SG_ 2566494206 ErDD1PrmrSdCrrntMnmmLmtSttng 24054;
BA_ "SPN" SG_ 2566494206 ErDD1PrmrSdCrrntMxmmLmtSttng 24055;
BA_ "SPN" SG_ 2566494206 ErDD1SndrSdCrrntMnmmLmtSttng 24056;
BA_ "SPN" SG_ 2566494206 ErDD1SndrSdCrrntMxmmLmtSttng 24057;
BA_ "SPN" SG_ 2566494462 ErDD1PrmrSdVltgMnmmLmtSttng 24050;
BA_ "SPN" SG_ 2566494462 ErDD1PrmrSdVltgMxmmLmtSttng 24051;
BA_ "SPN" SG_ 2566494462 ErDD1SndrSdVltgMnmmLmtSttng 24052;
BA_ "SPN" SG_ 2566494462 ErDD1SndrSdVltgMxmmLmtSttng 24053;
BA_ "SPN" SG_ 2365168126 ErDD1CntrllrInptIgntnVltg 24048;
BA_ "SPN" SG_ 2365168126 ErDD1CntrllrInptUnswthdSlVltg 24049;
BA_ "SPN" SG_ 2365168382 ErDcDc1PrimarySidePower 24044;
BA_ "SPN" SG_ 2365168382 ErDcDc1SecondarySidePower 24045;
BA_ "SPN" SG_ 2365168382 ErDD1PrmrSdNgtvTChsssGrndVltg 24046;
BA_ "SPN" SG_ 2365168382 ErDD1SndrSdNgtvTChsssGrndVltg 24047;
BA_ "SPN" SG_ 2365168638 ErDcDc1PrimarySideVoltage 24040;
BA_ "SPN" SG_ 2365168638 ErDcDc1SecondarySideVoltage 24041;
BA_ "SPN" SG_ 2365168638 ErDcDc1PrimarySideCurrent 24042;
BA_ "SPN" SG_ 2365168638 ErDcDc1SecondarySideCurrent 24043;
BA_ "SPN" SG_ 2365168894 ErDcDc1StatusCrc 24023;
BA_ "SPN" SG_ 2365168894 ErDcDc1StatusCounter 24024;
BA_ "SPN" SG_ 2365168894 ErDcDc1OperationalStatus 24025;
BA_ "SPN" SG_ 2365168894 ErDcDc1HvilStatus 24026;
BA_ "SPN" SG_ 2365168894 ErDcDc1LoadshedRequest 24027;
BA_ "SPN" SG_ 2365168894 ErDD1PwrLmtDTPrmrSdCrrntMnmm 24028;
BA_ "SPN" SG_ 2365168894 ErDD1PwrLmtDTPrmrSdCrrntMxmm 24029;
BA_ "SPN" SG_ 2365168894 ErDD1PwrLmtDTSndrSdCrrntMnmm 24030;
BA_ "SPN" SG_ 2365168894 ErDD1PwrLmtDTSndrSdCrrntMxmm 24031;
BA_ "SPN" SG_ 2365168894 ErDD1PwrLmtDTPrmrSdVltgMnmm 24032;
BA_ "SPN" SG_ 2365168894 ErDD1PwrLmtDTPrmrSdVltgMxmm 24033;
BA_ "SPN" SG_ 2365168894 ErDD1PwrLmtDTSndrSdVltgMnmm 24034;
BA_ "SPN" SG_ 2365168894 ErDD1PwrLmtDTSndrSdVltgMxmm 24035;
BA_ "SPN" SG_ 2365168894 ErDD1PwrLmtDTCnvrtrTmprtr 24036;
BA_ "SPN" SG_ 2365168894 ErDD1PwrLmtDTEltrnFltrTmprtr 24037;
BA_ "SPN" SG_ 2365168894 ErDD1PwrLmtDTPwrEltrnsTmprtr 24038;
BA_ "SPN" SG_ 2365168894 ErDD1PwrLmtDTUndfndRsn 24039;
BA_ "SPN" SG_ 2365169150 ErDcDc1CommandCrc 24019;
BA_ "SPN" SG_ 2365169150 ErDcDc1CommandCounter 24020;
BA_ "SPN" SG_ 2365169150 ErDcDc1OperationalCommand 24021;
BA_ "SPN" SG_ 2365169150 ErDcDc1OperationalSetpoint 24022;
BA_ "SPN" SG_ 2566495998 CabCo2ConcentrationStatus 23995;
BA_ "SPN" SG_ 2566495998 CabPressureStatus 23996;
BA_ "SPN" SG_ 2566495998 CabDustConcentrationStatus 23997;
BA_ "SPN" SG_ 2566496254 CabCo2Concentration 23989;
BA_ "SPN" SG_ 2566496254 CabPressure 23990;
BA_ "SPN" SG_ 2566496254 CabDustConcentration 23991;
BA_ "SPN" SG_ 2566496254 CabPressureSensorStatus 23992;
BA_ "SPN" SG_ 2566496254 CabCo2ConcentrationSensorStatus 23993;
BA_ "SPN" SG_ 2566496254 CDstCnntrtnSnsrStts 23994;
BA_ "SPN" SG_ 2566496510 AtWSttPpLOFwRtExtddR 23985;
BA_ "SPN" SG_ 2566496510 EsttdWSttPpLOFwRtExtddR 23986;
BA_ "SPN" SG_ 2566496510 AtWSttPpGBxLOFwRtExtddR 23987;
BA_ "SPN" SG_ 2566496510 EsttdWSttPpGBxLOFwRtExtddR 23988;
BA_ "SPN" SG_ 2566496766 EngnFlInjtnSstmDsrdOlPmpMtrSpd 23968;
BA_ "SPN" SG_ 2566496766 EngnFlInjtnSstmOlRl1Prssr 23969;
BA_ "SPN" SG_ 2566496766 EngnFlInjtnSstmOlRl2Prssr 23970;
BA_ "SPN" SG_ 2566496766 EFItSstOPpFwCtVvCd 23971;
BA_ "SPN" SG_ 2566496766 EFItSstOPssLttVvCd 23972;
BA_ "SPN" SG_ 2566496766 EngnFlInjtnSstmOlPmpMtrEnlCmmnd 23973;
BA_ "SPN" SG_ 2566497022 EF2ItMtR1PssExtddR 23963;
BA_ "SPN" SG_ 2566497022 EF2ItMtR2PssExtddR 23964;
BA_ "SPN" SG_ 2566497022 EngnFl2DsrdPmpMtrSpd 23965;
BA_ "SPN" SG_ 2566497022 EngnFl2PmpMtrEnlCmmnd 23966;
BA_ "SPN" SG_ 2566497022 EngnFl2PmpBpssVlvCmmnd 23967;
BA_ "SPN" SG_ 2566497278 EngnCtlstDvrtrAttr1Cmmnd 23962;
BA_ "SPN" SG_ 2566497278 EngnCtlstDvrtrAttr2Cmmnd 24301;
BA_ "SPN" SG_ 2566497534 FuelSpecificHumidity 23958;
BA_ "SPN" SG_ 2566497534 EngineChargeAirSpecificHumidity 23959;
BA_ "SPN" SG_ 2566497534 FuelRelativeHumidity 23960;
BA_ "SPN" SG_ 2566497534 EngineChargeAirRelativeHumidity 23961;
BA_ "SPN" SG_ 2566497790 Atttt2ExstPttCtSstDstT 23955;
BA_ "SPN" SG_ 2566497790 Atttt2ExstPttCtSstDstCt 23956;
BA_ "SPN" SG_ 2566498046 Atttt1ExstPttCtSstDstT 23953;
BA_ "SPN" SG_ 2566498046 Atttt1ExstPttCtSstDstCt 23954;
BA_ "SPN" SG_ 2566498302 Atttt2TtERtWtNDsExstFdDv 23951;
BA_ "SPN" SG_ 2566498302 Atttt2TtEvtCtWtNDsExstFdDv 23952;
BA_ "SPN" SG_ 2566498558 Aftrtrtmnt2SrIntkHghTmprtrTm 23949;
BA_ "SPN" SG_ 2566498558 Aftrtrtmnt2SrIntkHghTmprtrCnt 23950;
BA_ "SPN" SG_ 2566498814 Aftrtrtmnt2DslExhstFldFrznTm 23947;
BA_ "SPN" SG_ 2566498814 Aftrtrtmnt2DslExhstFldFrznCnt 23948;
BA_ "SPN" SG_ 2566499070 Aftrtrtmnt2SrMlfntnTm 23945;
BA_ "SPN" SG_ 2566499070 Aftrtrtmnt2SrMlfntnCnt 23946;
BA_ "SPN" SG_ 2566499326 Atttt2DsExstFdQtMtT 23943;
BA_ "SPN" SG_ 2566499326 Atttt2DsExstFdQtMtCt 23944;
BA_ "SPN" SG_ 2566499582 Atttt2DsExstFdT1EptT 23941;
BA_ "SPN" SG_ 2566499582 Atttt2DsExstFdT1EptCt 23942;
BA_ "SPN" SG_ 2566499838 AttttTtERtWtNDsExstFdDv 23939;
BA_ "SPN" SG_ 2566499838 AttttTtEvtCtWtNDsExstFdDv 23940;
BA_ "SPN" SG_ 2566500094 AftrtrtmntSrIntkHghTmprtrTm 23937;
BA_ "SPN" SG_ 2566500094 AftrtrtmntSrIntkHghTmprtrCnt 23938;
BA_ "SPN" SG_ 2566500350 Aftrtrtmnt1DslExhstFldFrznTm 23935;
BA_ "SPN" SG_ 2566500350 Aftrtrtmnt1DslExhstFldFrznCnt 23936;
BA_ "SPN" SG_ 2566500606 Aftrtrtmnt1SrMlfntnTm 23933;
BA_ "SPN" SG_ 2566500606 Aftrtrtmnt1SrMlfntnCnt 23934;
BA_ "SPN" SG_ 2566500862 Atttt1DsExstFdQtMtT 23931;
BA_ "SPN" SG_ 2566500862 Atttt1DsExstFdQtMtCt 23932;
BA_ "SPN" SG_ 2566501118 Atttt1DsExstFdT1EptT 23929;
BA_ "SPN" SG_ 2566501118 Atttt1DsExstFdT1EptCt 23930;
BA_ "SPN" SG_ 2499392766 SmltdMnsFrqnOffstExtnddRng 23909;
BA_ "SPN" SG_ 2566501886 AltrntrStpntVltgFdk 23893;
BA_ "SPN" SG_ 2566501886 AlternatorOutputVoltage 23894;
BA_ "SPN" SG_ 2566501886 AltrntrVltgRgltrTmprtr 23895;
BA_ "SPN" SG_ 2566501886 AlternatorExcitationCurrent 23896;
BA_ "SPN" SG_ 2566501886 AlternatorExcitationDutyCycle 23897;
BA_ "SPN" SG_ 2499417598 RtvPwrRmtInptCmpnstnFtr 23905;
BA_ "SPN" SG_ 2499417598 RlPwrRmtInptCmpnstnFtr 23906;
BA_ "SPN" SG_ 2163828734 EngineFuel2DeliveryPressure 24316;
BA_ "SPN" SG_ 2163828734 EngnFl2FltrDffrntlPrssr 24317;
BA_ "SPN" SG_ 2163828734 EngnFl2DlvrAsltPrssr 24318;
BA_ "SPN" SG_ 2163828734 EngnFltrdFl2DlvrPrssr 24319;
BA_ "SPN" SG_ 2163828734 EngnFltrdFl2DlvrAsltPrssr 24320;
BA_ "SPN" SG_ 2163828734 EngnFl2RltvDltrt1 24321;
BA_ "SPN" SG_ 2163828734 EngnFl2RltvDltrt2 24322;
BA_ "SPN" SG_ 2566482174 EngnCtlstDvrtrAttr1Pstn 24300;
BA_ "SPN" SG_ 2566482174 EngnCtlstDvrtrAttr2Pstn 24302;
BA_ "SPN" SG_ 2566482430 EldHsPrplsnSstmPwrStts 24296;
BA_ "SPN" SG_ 2566482430 EldHosVehicleMotionStatus 24297;
BA_ "SPN" SG_ 2566482430 EldHosVehicleDistance 24298;
BA_ "SPN" SG_ 2566482430 EldHosEngineHours 24299;
